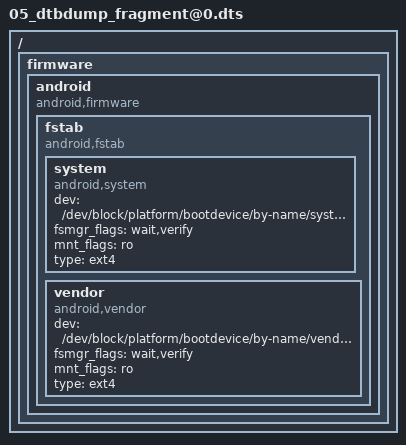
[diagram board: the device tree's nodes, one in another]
/dts-v1/;

/ {

	__fixups__ {
		accdet = "/fragment@17:target:0", "/fragment@62:target:0";
		apuart0 = "/fragment@24:target:0";
		audgpio = "/fragment@18:target:0";
		auxadc = "/fragment@42:target:0";
		chosen = "/fragment@0:target:0";
		consys = "/fragment@21:target:0";
		dsi_te = "/fragment@66:target:0";
		fpc_interrupt = "/fragment@36:target:0";
		goodix_fp = "/fragment@64:target:0";
		goodix_optical_fp = "/fragment@38:target:0";
		gpio = "/fragment@57:target:0";
		gpio_usage_mapping = "/fragment@56:target:0";
		gyro = "/fragment@61:target:0";
		i2c0 = "/fragment@34:target:0", "/fragment@44:target:0";
		i2c1 = "/fragment@45:target:0";
		i2c10 = "/fragment@54:target:0";
		i2c11 = "/fragment@55:target:0";
		i2c2 = "/fragment@46:target:0";
		i2c3 = "/fragment@4:target:0", "/fragment@7:target:0", "/fragment@13:target:0", "/fragment@47:target:0";
		i2c4 = "/fragment@48:target:0";
		i2c5 = "/fragment@11:target:0", "/fragment@49:target:0";
		i2c6 = "/fragment@50:target:0";
		i2c7 = "/fragment@51:target:0";
		i2c8 = "/fragment@52:target:0";
		i2c9 = "/fragment@53:target:0";
		irtx_pwm = "/fragment@26:target:0";
		kd_camera_hw1 = "/fragment@23:target:0", "/fragment@78:target:0";
		keypad = "/fragment@30:target:0", "/fragment@80:target:0";
		main_pmic = "/fragment@67:target:0";
		md1_sim1_hot_plug_eint = "/fragment@69:target:0";
		md1_sim2_hot_plug_eint = "/fragment@70:target:0";
		mediatek_phy_tuning = "/fragment@2:target:0";
		mrdump_ext_rst = "/fragment@58:target:0";
		msdc1 = "/fragment@32:target:0";
		msdc1_ins = "/fragment@60:target:0";
		mt6370_pmu = "/fragment@28:target:0";
		mt6370_typec = "/fragment@29:target:0";
		mt_pmic_vcama1_ldo_reg = "/fragment@23/__overlay__:cam0_vcama-supply:0", "/fragment@71:target:0", "/fragment@78/__overlay__:vcama-supply:0";
		mt_pmic_vcama2_ldo_reg = "/fragment@23/__overlay__:cam1_vcama-supply:0", "/fragment@72:target:0", "/fragment@78/__overlay__:vcama_sub-supply:0";
		mt_pmic_vcamd_ldo_reg = "/fragment@23/__overlay__:cam0_vcamd-supply:0", "/fragment@23/__overlay__:cam1_vcamd-supply:0", "/fragment@75:target:0", "/fragment@78/__overlay__:vcamd_sub-supply:0", "/fragment@78/__overlay__:vcamd-supply:0";
		mt_pmic_vcamio_ldo_reg = "/fragment@23/__overlay__:cam0_vcamio-supply:0", "/fragment@23/__overlay__:cam1_vcamio-supply:0", "/fragment@76:target:0", "/fragment@78/__overlay__:vcamio-supply:0", "/fragment@78/__overlay__:vcamio_sub-supply:0";
		mt_pmic_vio18_ldo_reg = "/fragment@36/__overlay__:vdd_io-supply:0";
		mt_pmic_vldo28_ldo_reg = "/fragment@77:target:0", "/fragment@78/__overlay__:vcamaf-supply:0", "/fragment@79/__overlay__:vtouch-supply:0";
		mt_pmic_vsim1_ldo_reg = "/fragment@73:target:0";
		mt_pmic_vsim2_ldo_reg = "/fragment@74:target:0";
		mtkfb = "/fragment@6:target:0";
		odm = "/fragment@1:target:0";
		oppo_fp_common = "/fragment@40:target:0";
		otg_iddig = "/fragment@15:target:0", "/fragment@65:target:0";
		pio = "/fragment@1/__overlay__/kpd_volume_up:interrupt-parent:0", "/fragment@1/__overlay__/kpd_volume_down:interrupt-parent:0", "/fragment@1/__overlay__/oppo_devinfo:Hw,sub_hwid_1:0", "/fragment@1/__overlay__/oppo_devinfo:Hw,sub_hwid_2:0", "/fragment@1/__overlay__/oppo_devinfo:Hw,main_hwid_5:0", "/fragment@1/__overlay__/oppo_devinfo:Hw,main_hwid_6:0", "/fragment@1/__overlay__/oppo_charger:qcom,chargerid_switch-gpio:0", "/fragment@1/__overlay__/oppo_charger:qcom,ship-gpio:0", "/fragment@1/__overlay__/oppo_charger:qcom,shortc-gpio:0", "/fragment@5:target:0", "/fragment@8:target:0", "/fragment@10:target:0", "/fragment@11/__overlay__/bq24190-charger@6b:interrupt-parent:0", "/fragment@11/__overlay__/bq25890h-charger@6a:interrupt-parent:0", "/fragment@12:target:0", "/fragment@13/__overlay__/dhall0-m1120@0f:interrupt-parent:0", "/fragment@13/__overlay__/dhall0-m1120@0f:dhall,irq-gpio:0", "/fragment@13/__overlay__/dhall0-m1120@0f:hall-power-gpio:0", "/fragment@13/__overlay__/dhall1-m1120@0c:interrupt-parent:0", "/fragment@13/__overlay__/dhall1-m1120@0c:dhall,irq-gpio:0", "/fragment@13/__overlay__/dhall1-m1120@0c:hall-power-gpio:0", "/fragment@14:target:0", "/fragment@16:target:0", "/fragment@19:target:0", "/fragment@20:target:0", "/fragment@22:target:0", "/fragment@25:target:0", "/fragment@27:target:0", "/fragment@28/__overlay__:mt6370,intr_gpio:0", "/fragment@29/__overlay__:mt6370pd,intr_gpio:0", "/fragment@30/__overlay__:keypad,volume-up:0", "/fragment@30/__overlay__:keypad,volume-down:0", "/fragment@31:target:0", "/fragment@33:target:0", "/fragment@34/__overlay__/synatpics_td4310@21:interrupt-parent:0", "/fragment@34/__overlay__/synatpics_td4310@21:irq-gpio:0", "/fragment@34/__overlay__/synatpics_td4330@20:interrupt-parent:0", "/fragment@34/__overlay__/synatpics_td4330@20:irq-gpio:0", "/fragment@34/__overlay__/synatpics_td4330@20:reset-gpio:0", "/fragment@34/__overlay__/himax_hx83112b@48:interrupt-parent:0", "/fragment@34/__overlay__/himax_hx83112b@48:irq-gpio:0", "/fragment@34/__overlay__/himax_hx83112b@48:reset-gpio:0", "/fragment@34/__overlay__/nova_nt36672@62:interrupt-parent:0", "/fragment@34/__overlay__/nova_nt36672@62:irq-gpio:0", "/fragment@34/__overlay__/nova_nt36672@62:reset-gpio:0", "/fragment@35:target:0", "/fragment@36/__overlay__:fpc,irq-gpio:0", "/fragment@36/__overlay__:fpc,reset-gpio:0", "/fragment@36/__overlay__:fpc,vdd-en:0", "/fragment@36/__overlay__:fpc,gpio_cs:0", "/fragment@37:target:0", "/fragment@38/__overlay__:interrupt-parent:0", "/fragment@38/__overlay__:goodix,gpio_irq:0", "/fragment@38/__overlay__:goodix,gpio_reset:0", "/fragment@38/__overlay__:goodix,gpio_ldo:0", "/fragment@38/__overlay__:goodix,gpio_cs:0", "/fragment@39/__overlay__/fingerprint@0:ldo_gpio:0", "/fragment@41:target:0", "/fragment@45/__overlay__/alsps@51:interrupt-parent:0", "/fragment@56/__overlay__:GPIO_SIM2_SIO:0", "/fragment@56/__overlay__:GPIO_SIM2_SRST:0", "/fragment@56/__overlay__:GPIO_SIM2_SCLK:0", "/fragment@56/__overlay__:GPIO_SIM1_SCLK:0", "/fragment@56/__overlay__:GPIO_SIM1_SRST:0", "/fragment@56/__overlay__:GPIO_SIM1_SIO:0", "/fragment@56/__overlay__:GPIO_SIM2_HOT_PLUG:0", "/fragment@56/__overlay__:GPIO_SIM1_HOT_PLUG:0", "/fragment@58/__overlay__:interrupt-parent:0", "/fragment@58/__overlay__:deb-gpios:0", "/fragment@59/__overlay__:interrupt-parent:0", "/fragment@60/__overlay__:interrupt-parent:0", "/fragment@60/__overlay__:deb-gpios:0", "/fragment@61/__overlay__:interrupt-parent:0", "/fragment@62/__overlay__:interrupt-parent:0", "/fragment@62/__overlay__:deb-gpios:0", "/fragment@63/__overlay__:interrupt-parent:0", "/fragment@64/__overlay__:interrupt-parent:0", "/fragment@65/__overlay__:interrupt-parent:0", "/fragment@66/__overlay__:interrupt-parent:0", "/fragment@67/__overlay__:interrupt-parent:0", "/fragment@68/__overlay__:interrupt-parent:0";
		pmic_clock_buffer_ctrl = "/fragment@43:target:0";
		scp = "/fragment@3:target:0";
		smart_pa = "/fragment@68:target:0";
		spi0 = "/fragment@39:target:0";
		subpmic_pmu_eint = "/fragment@63:target:0";
		touch = "/fragment@9:target:0", "/fragment@59:target:0", "/fragment@79:target:0";
	};

	__local_fixups__ {

		fragment@1 {

			__overlay__ {

				oppo_charger {
					pinctrl-0 = <0x0>;
					pinctrl-1 = <0x0>;
					pinctrl-2 = <0x0>;
					pinctrl-3 = <0x0>;
					pinctrl-4 = <0x0>;
					pinctrl-5 = <0x0>;
				};

				oppo_devinfo {
					pinctrl-0 = <0x0>;
					pinctrl-1 = <0x0 0x4>;
					pinctrl-2 = <0x0 0x4>;
					pinctrl-3 = <0x0>;
					pinctrl-4 = <0x0>;
				};
			};
		};

		fragment@13 {

			__overlay__ {

				dhall0-m1120@0f {
					pinctrl-0 = <0x0>;
					pinctrl-1 = <0x0>;
					pinctrl-2 = <0x0>;
				};

				dhall1-m1120@0c {
					pinctrl-0 = <0x0>;
					pinctrl-1 = <0x0>;
					pinctrl-2 = <0x0>;
				};
			};
		};

		fragment@15 {

			__overlay__ {
				pinctrl-0 = <0x0>;
				pinctrl-1 = <0x0>;
				pinctrl-2 = <0x0>;
			};
		};

		fragment@18 {

			__overlay__ {
				pinctrl-0 = <0x0>;
				pinctrl-1 = <0x0>;
				pinctrl-10 = <0x0>;
				pinctrl-11 = <0x0>;
				pinctrl-2 = <0x0>;
				pinctrl-3 = <0x0>;
				pinctrl-4 = <0x0>;
				pinctrl-5 = <0x0>;
				pinctrl-6 = <0x0>;
				pinctrl-7 = <0x0>;
				pinctrl-8 = <0x0>;
				pinctrl-9 = <0x0>;
			};
		};

		fragment@21 {

			__overlay__ {
				pinctrl-0 = <0x0>;
				pinctrl-1 = <0x0>;
				pinctrl-2 = <0x0>;
				pinctrl-3 = <0x0>;
			};
		};

		fragment@23 {

			__overlay__ {
				pinctrl-0 = <0x0>;
				pinctrl-1 = <0x0>;
				pinctrl-10 = <0x0>;
				pinctrl-11 = <0x0>;
				pinctrl-12 = <0x0>;
				pinctrl-13 = <0x0>;
				pinctrl-14 = <0x0>;
				pinctrl-15 = <0x0>;
				pinctrl-16 = <0x0>;
				pinctrl-17 = <0x0>;
				pinctrl-18 = <0x0>;
				pinctrl-19 = <0x0>;
				pinctrl-2 = <0x0>;
				pinctrl-20 = <0x0>;
				pinctrl-21 = <0x0>;
				pinctrl-22 = <0x0>;
				pinctrl-23 = <0x0>;
				pinctrl-24 = <0x0>;
				pinctrl-25 = <0x0>;
				pinctrl-26 = <0x0>;
				pinctrl-27 = <0x0>;
				pinctrl-28 = <0x0>;
				pinctrl-29 = <0x0>;
				pinctrl-3 = <0x0>;
				pinctrl-30 = <0x0>;
				pinctrl-31 = <0x0>;
				pinctrl-32 = <0x0>;
				pinctrl-33 = <0x0>;
				pinctrl-4 = <0x0>;
				pinctrl-5 = <0x0>;
				pinctrl-6 = <0x0>;
				pinctrl-7 = <0x0>;
				pinctrl-8 = <0x0>;
				pinctrl-9 = <0x0>;
			};
		};

		fragment@24 {

			__overlay__ {
				pinctrl-0 = <0x0>;
				pinctrl-1 = <0x0>;
				pinctrl-2 = <0x0>;
				pinctrl-3 = <0x0>;
				pinctrl-4 = <0x0>;
				pinctrl-5 = <0x0>;
				pinctrl-6 = <0x0>;
			};
		};

		fragment@26 {

			__overlay__ {
				pinctrl-0 = <0x0>;
				pinctrl-1 = <0x0>;
			};
		};

		fragment@30 {

			__overlay__ {
				pinctrl-0 = <0x0>;
				pinctrl-1 = <0x0>;
			};
		};

		fragment@32 {

			__overlay__ {
				pinctrl-0 = <0x0>;
				pinctrl-1 = <0x0>;
			};
		};

		fragment@36 {

			__overlay__ {
				pinctrl-0 = <0x0 0x4 0x8>;
				pinctrl-1 = <0x0>;
			};
		};

		fragment@38 {

			__overlay__ {
				pinctrl-0 = <0x0>;
				pinctrl-1 = <0x0>;
				pinctrl-2 = <0x0>;
				pinctrl-3 = <0x0>;
				pinctrl-4 = <0x0>;
			};
		};

		fragment@6 {

			__overlay__ {
				pinctrl-0 = <0x0>;
				pinctrl-1 = <0x0>;
				pinctrl-10 = <0x0>;
				pinctrl-11 = <0x0>;
				pinctrl-12 = <0x0>;
				pinctrl-2 = <0x0>;
				pinctrl-3 = <0x0>;
				pinctrl-4 = <0x0>;
				pinctrl-5 = <0x0>;
				pinctrl-6 = <0x0>;
				pinctrl-7 = <0x0>;
				pinctrl-8 = <0x0>;
				pinctrl-9 = <0x0>;
			};
		};

		fragment@7 {

			__overlay__ {

				tfa98xx@35 {
					pinctrl-0 = <0x0>;
					pinctrl-1 = <0x0>;
					pinctrl-2 = <0x0>;
				};
			};
		};

		fragment@9 {

			__overlay__ {
				pinctrl-0 = <0x0>;
				pinctrl-1 = <0x0>;
				pinctrl-2 = <0x0>;
				pinctrl-3 = <0x0>;
				pinctrl-4 = <0x0>;
				pinctrl-5 = <0x0>;
			};
		};
	};

	__symbols__ {
		alsps_mtk = "/fragment@45/__overlay__/alsps@51";
		aud_clk_mosi_off = "/fragment@19/__overlay__/aud_clk_mosi_off";
		aud_clk_mosi_on = "/fragment@19/__overlay__/aud_clk_mosi_on";
		aud_dat_miso_off = "/fragment@19/__overlay__/aud_dat_miso_off";
		aud_dat_miso_on = "/fragment@19/__overlay__/aud_dat_miso_on";
		aud_dat_mosi_off = "/fragment@19/__overlay__/aud_dat_mosi_off";
		aud_dat_mosi_on = "/fragment@19/__overlay__/aud_dat_mosi_on";
		aud_pins_hpamp_high = "/fragment@19/__overlay__/audhpamphigh";
		aud_pins_hpamp_low = "/fragment@19/__overlay__/audhpamplow";
		aud_pins_i2s0_mode0 = "/fragment@19/__overlay__/audi2s0mode0";
		aud_pins_i2s0_mode1 = "/fragment@19/__overlay__/audi2s0mode1";
		aud_pins_i2s1_mode0 = "/fragment@19/__overlay__/audi2s1mode0";
		aud_pins_i2s1_mode1 = "/fragment@19/__overlay__/audi2s1mode1";
		barometer_mtk = "/fragment@45/__overlay__/barometer@77";
		bat_gm30 = "/fragment@1/__overlay__/bat_gm30";
		camera_main_af_mtk = "/fragment@48/__overlay__/camera_main_af@72";
		camera_main_eeprom_mtk = "/fragment@48/__overlay__/camera_main_eeprom@50";
		camera_main_mtk = "/fragment@48/__overlay__/camera_main@1a";
		camera_main_two_af_mtk = "/fragment@48/__overlay__/camera_main_two_af@72";
		camera_main_two_eeprom_mtk = "/fragment@48/__overlay__/camera_main_two_eeprom@51";
		camera_main_two_mtk = "/fragment@48/__overlay__/camera_main_two@10";
		camera_pins_cam0_mclk_2ma = "/fragment@22/__overlay__/camera_pins_cam0_mclk_2ma";
		camera_pins_cam0_mclk_4ma = "/fragment@22/__overlay__/camera_pins_cam0_mclk_4ma";
		camera_pins_cam0_mclk_6ma = "/fragment@22/__overlay__/camera_pins_cam0_mclk_6ma";
		camera_pins_cam0_mclk_8ma = "/fragment@22/__overlay__/camera_pins_cam0_mclk_8ma";
		camera_pins_cam0_mclk_off = "/fragment@22/__overlay__/camera_pins_cam0_mclk_off";
		camera_pins_cam0_pnd_0 = "/fragment@22/__overlay__/cam0@2";
		camera_pins_cam0_pnd_1 = "/fragment@22/__overlay__/cam0@3";
		camera_pins_cam0_rst_0 = "/fragment@22/__overlay__/cam0@0";
		camera_pins_cam0_rst_1 = "/fragment@22/__overlay__/cam0@1";
		camera_pins_cam0_vcamd_0 = "/fragment@22/__overlay__/cam0@vcam0";
		camera_pins_cam0_vcamd_1 = "/fragment@22/__overlay__/cam0@vcam1";
		camera_pins_cam1_mclk_2ma = "/fragment@22/__overlay__/camera_pins_cam1_mclk_2ma";
		camera_pins_cam1_mclk_4ma = "/fragment@22/__overlay__/camera_pins_cam1_mclk_4ma";
		camera_pins_cam1_mclk_6ma = "/fragment@22/__overlay__/camera_pins_cam1_mclk_6ma";
		camera_pins_cam1_mclk_8ma = "/fragment@22/__overlay__/camera_pins_cam1_mclk_8ma";
		camera_pins_cam1_mclk_off = "/fragment@22/__overlay__/camera_pins_cam1_mclk_off";
		camera_pins_cam1_pnd_0 = "/fragment@22/__overlay__/cam1@2";
		camera_pins_cam1_pnd_1 = "/fragment@22/__overlay__/cam1@3";
		camera_pins_cam1_rst_0 = "/fragment@22/__overlay__/cam1@0";
		camera_pins_cam1_rst_1 = "/fragment@22/__overlay__/cam1@1";
		camera_pins_cam2_mclk_2ma = "/fragment@22/__overlay__/camera_pins_cam2_mclk_2ma";
		camera_pins_cam2_mclk_4ma = "/fragment@22/__overlay__/camera_pins_cam2_mclk_4ma";
		camera_pins_cam2_mclk_6ma = "/fragment@22/__overlay__/camera_pins_cam2_mclk_6ma";
		camera_pins_cam2_mclk_8ma = "/fragment@22/__overlay__/camera_pins_cam2_mclk_8ma";
		camera_pins_cam2_mclk_off = "/fragment@22/__overlay__/camera_pins_cam2_mclk_off";
		camera_pins_cam2_pnd_0 = "/fragment@22/__overlay__/cam2@3";
		camera_pins_cam2_pnd_1 = "/fragment@22/__overlay__/cam2@4";
		camera_pins_cam2_rst_0 = "/fragment@22/__overlay__/cam2@0";
		camera_pins_cam2_rst_1 = "/fragment@22/__overlay__/cam2@1";
		camera_pins_cam2_vcama_0 = "/fragment@22/__overlay__/cam1@vcam2";
		camera_pins_cam2_vcama_1 = "/fragment@22/__overlay__/cam1@vcam3";
		camera_pins_cam2_vcamd_0 = "/fragment@22/__overlay__/cam2@vcam0";
		camera_pins_cam2_vcamd_1 = "/fragment@22/__overlay__/cam1@vcam1";
		camera_pins_default = "/fragment@22/__overlay__/camdefault";
		camera_sub_eeprom_mtk = "/fragment@48/__overlay__/camera_sub_eeprom@54";
		camera_sub_mtk = "/fragment@48/__overlay__/camera_sub@35";
		cap_touch_mtk = "/fragment@44/__overlay__/cap_touch@5d";
		ccu_sensor_i2c_4_hw_mtk = "/fragment@48/__overlay__/ccu_sensor_i2c_4_hw@33";
		charger_pins_default = "/fragment@12/__overlay__/eint0default";
		charger_pins_eint_output0 = "/fragment@12/__overlay__/charger_gpio_as_output_low";
		charger_pins_eint_output1 = "/fragment@12/__overlay__/charger_gpio_as_output_high";
		consys_pins_default = "/fragment@20/__overlay__/consys_default";
		ctp_pins_default = "/fragment@10/__overlay__/eint0default";
		ctp_pins_eint_as_int = "/fragment@10/__overlay__/eint@0";
		ctp_pins_eint_output0 = "/fragment@10/__overlay__/eintoutput0";
		ctp_pins_eint_output1 = "/fragment@10/__overlay__/eintoutput1";
		ctp_pins_rst_output0 = "/fragment@10/__overlay__/rstoutput0";
		ctp_pins_rst_output1 = "/fragment@10/__overlay__/rstoutput1";
		fpc_irq_default = "/fragment@35/__overlay__/fpc_irq_default";
		fpc_pwr_default = "/fragment@35/__overlay__/fpc_pwr_default";
		fpc_reset_default = "/fragment@35/__overlay__/fpc_reset_default";
		fuelgauge = "/fragment@1/__overlay__/fuelgauge";
		goodix_irq_no_pull = "/fragment@37/__overlay__/goodix_irq_no_pull";
		goodix_irq_out_low = "/fragment@37/__overlay__/goodix_irq_out_low";
		goodix_ldo_default = "/fragment@37/__overlay__/goodix_ldo_default";
		goodix_reset_default = "/fragment@37/__overlay__/goodix_reset_default";
		gpio41_gpio_mode = "/fragment@16/__overlay__/id_output_low";
		gpio41_mode1_iddig = "/fragment@16/__overlay__/id_init";
		gpio_fpc_cs_func = "/fragment@35/__overlay__/gpio_fpc_cs_func";
		gpio_goodix_cs_func = "/fragment@37/__overlay__/gpio_goodix_cs_func";
		gpslna_pins_init = "/fragment@20/__overlay__/gpslna@0";
		gpslna_pins_oh = "/fragment@20/__overlay__/gpslna@1";
		gpslna_pins_ol = "/fragment@20/__overlay__/gpslna@2";
		hall0_interrupt_input = "/fragment@14/__overlay__/hall0_interrupt_input";
		hall1_interrupt_input = "/fragment@14/__overlay__/hall1_interrupt_input";
		hall_power_down = "/fragment@14/__overlay__/hall_power_down";
		hall_power_up = "/fragment@14/__overlay__/hall_power_up";
		hw_main_id5_active = "/fragment@41/__overlay__/active@id5";
		hw_main_id6_active = "/fragment@41/__overlay__/active@id6";
		hw_pins_default = "/fragment@41/__overlay__/default@hw_sub_id";
		hw_pins_sub_id1_active = "/fragment@41/__overlay__/active@id1";
		hw_pins_sub_id1_sleep = "/fragment@41/__overlay__/sleep@id1";
		hw_pins_sub_id2_active = "/fragment@41/__overlay__/active@id2";
		hw_pins_sub_id2_sleep = "/fragment@41/__overlay__/sleep@id2";
		iddig_default = "/fragment@16/__overlay__/id_default";
		irtx_gpio_led_default = "/fragment@27/__overlay__/irtx_gpio_led_def@gpio90";
		irtx_gpio_led_set = "/fragment@27/__overlay__/irtx_gpio_led_set@gpio90";
		kpd_volume_down = "/fragment@1/__overlay__/kpd_volume_down";
		kpd_volume_up = "/fragment@1/__overlay__/kpd_volume_up";
		led0 = "/fragment@1/__overlay__/led@0";
		led1 = "/fragment@1/__overlay__/led@1";
		led2 = "/fragment@1/__overlay__/led@2";
		led3 = "/fragment@1/__overlay__/led@3";
		led4 = "/fragment@1/__overlay__/led@4";
		led5 = "/fragment@1/__overlay__/led@5";
		led6 = "/fragment@1/__overlay__/led@6";
		msdc1_off = "/fragment@33/__overlay__/sd0@1";
		msdc1_on = "/fragment@33/__overlay__/sd0@0";
		msensor_mtk = "/fragment@45/__overlay__/msensor@0c";
		mtkfb_pins_default = "/fragment@5/__overlay__/default";
		mtkfb_pins_lcd_1p8_en0 = "/fragment@5/__overlay__/lcd_1p8_en0_gpio";
		mtkfb_pins_lcd_1p8_en1 = "/fragment@5/__overlay__/lcd_1p8_en1_gpio";
		mtkfb_pins_lcd_bias_enn0 = "/fragment@5/__overlay__/lcd_bias_enn0_gpio";
		mtkfb_pins_lcd_bias_enn1 = "/fragment@5/__overlay__/lcd_bias_enn1_gpio";
		mtkfb_pins_lcd_bias_enp0 = "/fragment@5/__overlay__/lcd_bias_enp0_gpio";
		mtkfb_pins_lcd_bias_enp1 = "/fragment@5/__overlay__/lcd_bias_enp1_gpio";
		mtkfb_pins_lcd_bl_en0 = "/fragment@5/__overlay__/lcd_bl_en0_gpio";
		mtkfb_pins_lcd_bl_en1 = "/fragment@5/__overlay__/lcd_bl_en1_gpio";
		mtkfb_pins_lcm_reset0 = "/fragment@5/__overlay__/lcm_rst_out0_gpio";
		mtkfb_pins_lcm_reset1 = "/fragment@5/__overlay__/lcm_rst_out1_gpio";
		mtkfb_pins_mode_te_gpio = "/fragment@5/__overlay__/mode_te_gpio";
		mtkfb_pins_mode_te_te = "/fragment@5/__overlay__/mode_te_te";
		nfc_mtk = "/fragment@47/__overlay__/nfc@08";
		oppo_charger = "/fragment@1/__overlay__/oppo_charger";
		oppo_devinfo = "/fragment@1/__overlay__/oppo_devinfo";
		oppo_fp = "/fragment@39/__overlay__/fingerprint@0";
		oppo_project = "/fragment@1/__overlay__/oppo_project";
		oppo_sensor = "/fragment@1/__overlay__/oppo_sensor";
		ship_active_gpio = "/fragment@12/__overlay__/ship_active";
		ship_sleep_gpio = "/fragment@12/__overlay__/ship_sleep";
		shortc_active_gpio = "/fragment@12/__overlay__/shortc_active";
		slave_charger_mtk = "/fragment@50/__overlay__/slave_charger@4b";
		speaker_amp_mtk = "/fragment@50/__overlay__/speaker_amp@34";
		strobe_main_mtk = "/fragment@48/__overlay__/strobe_main@63";
		subpmic_pmu_mtk = "/fragment@49/__overlay__/subpmic_pmu@34";
		tfa98xxresetdefault = "/fragment@8/__overlay__/tfa98xxrstdefault";
		tfa98xxresethigh = "/fragment@8/__overlay__/tfa98xxrsthigh";
		tfa98xxresetlow = "/fragment@8/__overlay__/tfa98xxrstlow";
		uart0_gpio_def_cfg = "/fragment@25/__overlay__/uart0gpiodefault";
		uart0_rx_clr_cfg = "/fragment@25/__overlay__/uart0_rx_clear@gpio95";
		uart0_rx_gpio_input2 = "/fragment@25/__overlay__/uart0_rx_gpio@gpio95";
		uart0_rx_set_cfg = "/fragment@25/__overlay__/uart0_rx_set@gpio95";
		uart0_tx_clr_cfg = "/fragment@25/__overlay__/uart0_tx_clear@gpio96";
		uart0_tx_gpio_input2 = "/fragment@25/__overlay__/uart0_tx_gpio@gpio96";
		uart0_tx_set_cfg = "/fragment@25/__overlay__/uart0_tx_set@gpio96";
		usb_type_c_mtk = "/fragment@49/__overlay__/usb_type_c@4e";
		vibrator0 = "/fragment@1/__overlay__/vibrator@0";
		volume_down_gpio_eint = "/fragment@31/__overlay__/volume_down@0";
		volume_up_gpio_eint = "/fragment@31/__overlay__/volume_up@0";
	};

	firmware {

		android {
			compatible = "android,firmware";

			fstab {
				compatible = "android,fstab";

				system {
					compatible = "android,system";
					dev = "/dev/block/platform/bootdevice/by-name/system";
					fsmgr_flags = "wait,verify";
					mnt_flags = "ro";
					type = "ext4";
				};

				vendor {
					compatible = "android,vendor";
					dev = "/dev/block/platform/bootdevice/by-name/vendor";
					fsmgr_flags = "wait,verify";
					mnt_flags = "ro";
					type = "ext4";
				};
			};
		};
	};

	fragment@0 {
		target = <0xffffffff>;

		__overlay__ {
			atag,videolfb-fb_base_h = <0x0>;
			atag,videolfb-fb_base_l = "^`P";
			atag,videolfb-fps = <0x1770>;
			atag,videolfb-islcm_inited = <0x0>;
			atag,videolfb-islcmfound = <0x1>;
			atag,videolfb-lcmname = "nt35595_fhd_dsi_cmd_truly_nt50358_drv";
			atag,videolfb-vramSize = <0x17bb000>;
		};
	};

	fragment@1 {
		target = <0xffffffff>;

		__overlay__ {

			bat_gm30 {
				CAR_TUNE_VALUE = <0x64>;
				DIFFERENCE_FULLOCV_ITH = <0xc8>;
				EMBEDDED_SEL = <0x1>;
				FG_METER_RESISTANCE = <0x4b>;
				KEEP_100_PERCENT = <0x0>;
				PMIC_MIN_VOL = <0x84d0>;
				PMIC_SHUTDOWN_CURRENT = <0x14>;
				POWERON_SYSTEM_IBOOT = <0x1f4>;
				Q_MAX_SYS_VOLTAGE_BAT0 = <0xd16>;
				Q_MAX_SYS_VOLTAGE_BAT1 = <0xd16>;
				Q_MAX_SYS_VOLTAGE_BAT2 = <0xd16>;
				Q_MAX_SYS_VOLTAGE_BAT3 = <0xd16>;
				R_FG_VALUE = <0xa>;
				SHUTDOWN_1_TIME = <0x3c>;
				SHUTDOWN_GAUGE0_VOLTAGE = <0x84d0>;
				TEMPERATURE_T0 = <0x32>;
				TEMPERATURE_T1 = <0x19>;
				TEMPERATURE_T2 = <0xa>;
				TEMPERATURE_T3 = <0x0>;
				TEMPERATURE_T4 = <0xfffffff6>;
				battery0_profile_t0 = <0x0 0xa9b0 0x339 0x14f 0xa937 0x3ae 0x29f 0xa8c2 0x3f1 0x3ee 0xa850 0x401 0x53e 0xa7d4 0x3f0 0x68d 0xa75b 0x3e8 0x7dd 0xa6e2 0x3e8 0x92c 0xa669 0x3e8 0xa7c 0xa5f8 0x3fb 0xbcb 0xa58c 0x41a 0xd1b 0xa51a 0x41a 0xe6a 0xa49e 0x406 0xfb9 0xa41f 0x3ed 0x1109 0xa3b4 0x40e 0x1258 0xa344 0x41a 0x13a8 0xa2d2 0x41a 0x14f7 0xa260 0x41a 0x1647 0xa1ee 0x41a 0x1796 0xa17d 0x41a 0x18e6 0xa10f 0x41a 0x1a35 0xa0a3 0x426 0x1b85 0xa038 0x42f 0x1cd4 0x9fcd 0x41e 0x1e23 0x9f61 0x41a 0x1f73 0x9ef9 0x41e 0x20c2 0x9e9b 0x42f 0x2212 0x9e3c 0x440 0x2361 0x9dd9 0x44c 0x24b1 0x9d6e 0x44c 0x2600 0x9d0d 0x44c 0x2750 0x9cb1 0x451 0x289f 0x9c5a 0x462 0x29ef 0x9c03 0x465 0x2b3e 0x9bb0 0x470 0x2c8d 0x9b66 0x492 0x2ddd 0x9b15 0x4a5 0x2f2c 0x9ac1 0x4b0 0x307c 0x9a6a 0x4b0 0x31cb 0x9a1f 0x4eb 0x331b 0x99ca 0x50d 0x346a 0x9966 0x4fd 0x35ba 0x98ca 0x491 0x3709 0x983f 0x437 0x3859 0x97d1 0x403 0x39a8 0x9786 0x411 0x3af7 0x973f 0x412 0x3c47 0x96fc 0x401 0x3d96 0x96bf 0x3f1 0x3ee6 0x9683 0x3e8 0x4035 0x9646 0x3e8 0x4185 0x9616 0x3f9 0x42d4 0x95eb 0x40a 0x4424 0x95c2 0x419 0x4573 0x958c 0x409 0x46c3 0x955e 0x40a 0x4812 0x9536 0x41a 0x4961 0x950d 0x41a 0x4ab1 0x94e9 0x424 0x4c00 0x94c6 0x431 0x4d50 0x949d 0x420 0x4e9f 0x9479 0x424 0x4fef 0x9458 0x435 0x513e 0x9436 0x446 0x528e 0x9419 0x44c 0x53dd 0x93ff 0x451 0x552d 0x93ea 0x473 0x567c 0x93d2 0x48a 0x57cb 0x93b3 0x494 0x591b 0x9384 0x483 0x5a6a 0x933d 0x443 0x5bba 0x92f1 0x401 0x5d09 0x92b5 0x401 0x5e59 0x9281 0x40d 0x5fa8 0x9252 0x416 0x60f8 0x9223 0x405 0x6247 0x91fe 0x41b 0x6397 0x91db 0x42a 0x64e6 0x91b2 0x408 0x6635 0x9195 0x41c 0x6785 0x9174 0x433 0x68d4 0x9144 0x433 0x6a24 0x9109 0x425 0x6b73 0x90cd 0x41a 0x6cc3 0x9091 0x41a 0x6e12 0x9054 0x428 0x6f62 0x9015 0x42d 0x70b1 0x8fd2 0x41c 0x7201 0x8fb8 0x40b 0x7350 0x8fa9 0x40f 0x749f 0x8fa2 0x431 0x75ef 0x8f96 0x462 0x773e 0x8f74 0x494 0x788e 0x8f37 0x4c6 0x79dd 0x8e10 0x48a 0x7b2d 0x8c7a 0x47c 0x7c7c 0x8a6e 0x4ae 0x7dcc 0x8722 0x4f2 0x7f1b 0x8167 0x797 0x806b 0x7841 0x7d0 0x81ba 0x7706 0x52d>;
				battery0_profile_t0_num = <0x64>;
				battery0_profile_t1 = <0x0 0xa9ce 0x47e 0x14f 0xa948 0x4e3 0x29f 0xa8c5 0x514 0x3ee 0xa846 0x515 0x53e 0xa7ca 0x537 0x68d 0xa754 0x53d 0x7dd 0xa6e2 0x52c 0x92c 0xa669 0x51b 0xa7c 0xa5f8 0x527 0xbcb 0xa58b 0x545 0xd1b 0xa50b 0x534 0xe6a 0xa498 0x52d 0xfb9 0xa42c 0x531 0x1109 0xa3ba 0x552 0x1258 0xa348 0x55f 0x13a8 0xa2d7 0x561 0x14f7 0xa26b 0x572 0x1647 0xa1f6 0x557 0x1796 0xa17d 0x536 0x18e6 0xa112 0x568 0x1a35 0xa0a7 0x578 0x1b85 0xa03d 0x578 0x1cd4 0x9fd8 0x578 0x1e23 0x9f73 0x584 0x1f73 0x9f11 0x595 0x20c2 0x9eb8 0x5a6 0x2212 0x9e56 0x5b7 0x2361 0x9dee 0x5c3 0x24b1 0x9d7c 0x5c3 0x2600 0x9d15 0x5dd 0x2750 0x9cb2 0x5fa 0x289f 0x9c54 0x60a 0x29ef 0x9bfb 0x61b 0x2b3e 0x9ba6 0x62c 0x2c8d 0x9b55 0x63d 0x2ddd 0x9b14 0x65c 0x2f2c 0x9ad2 0x678 0x307c 0x9a89 0x689 0x31cb 0x9a33 0x699 0x331b 0x99d7 0x69e 0x346a 0x9973 0x68d 0x35ba 0x98eb 0x616 0x3709 0x9866 0x59c 0x3859 0x97ed 0x538 0x39a8 0x9792 0x51e 0x3af7 0x9746 0x51b 0x3c47 0x9709 0x52c 0x3d96 0x96d3 0x53c 0x3ee6 0x969a 0x538 0x4035 0x965c 0x515 0x4185 0x9626 0x514 0x42d4 0x95f7 0x51c 0x4424 0x95cf 0x52d 0x4573 0x95a0 0x52d 0x46c3 0x9574 0x535 0x4812 0x954c 0x546 0x4961 0x9524 0x546 0x4ab1 0x94fb 0x53d 0x4c00 0x94d3 0x52e 0x4d50 0x94b8 0x550 0x4e9f 0x9499 0x55f 0x4fef 0x9478 0x560 0x513e 0x945d 0x571 0x528e 0x943f 0x578 0x53dd 0x941e 0x579 0x552d 0x940a 0x58a 0x567c 0x93f6 0x5a5 0x57cb 0x93e0 0x5c1 0x591b 0x93bf 0x5b0 0x5a6a 0x939d 0x595 0x5bba 0x937b 0x575 0x5d09 0x9359 0x565 0x5e59 0x9333 0x554 0x5fa8 0x930a 0x540 0x60f8 0x92db 0x51f 0x6247 0x92b5 0x514 0x6397 0x9293 0x51b 0x64e6 0x9271 0x53d 0x6635 0x924f 0x546 0x6785 0x922e 0x54a 0x68d4 0x920c 0x55b 0x6a24 0x91d7 0x552 0x6b73 0x919c 0x54a 0x6cc3 0x9166 0x55b 0x6e12 0x9130 0x56c 0x6f62 0x90f1 0x573 0x70b1 0x90a1 0x562 0x7201 0x9066 0x551 0x7350 0x9040 0x551 0x749f 0x9039 0x573 0x75ef 0x9032 0x5a2 0x773e 0x9025 0x5cf 0x788e 0x900a 0x5f0 0x79dd 0x8fb0 0x612 0x7b2d 0x8edd 0x61b 0x7c7c 0x8d4a 0x5f9 0x7dcc 0x8aeb 0x640 0x7f1b 0x87b3 0x6be 0x806b 0x8374 0x777 0x81ba 0x77c4 0x6bd>;
				battery0_profile_t1_num = <0x64>;
				battery0_profile_t2 = <0x0 0xa956 0x8b1 0x14f 0xa8b5 0x82b 0x29f 0xa825 0x7fa 0x3ee 0xa7a6 0x81b 0x53e 0xa726 0x81b 0x68d 0xa6aa 0x824 0x7dd 0xa631 0x834 0x92c 0xa5b9 0x834 0xa7c 0xa544 0x846 0xbcb 0xa4d1 0x865 0xd1b 0xa456 0x854 0xe6a 0xa3e0 0x84d 0xfb9 0xa36e 0x84f 0x1109 0xa2fc 0x860 0x1258 0xa28e 0x870 0x13a8 0xa222 0x87f 0x14f7 0xa1b0 0x87f 0x1647 0xa142 0x88a 0x1796 0xa0d7 0x89a 0x18e6 0xa06b 0x8ab 0x1a35 0xa004 0x8b1 0x1b85 0x9fa2 0x8b6 0x1cd4 0x9f4b 0x8d8 0x1e23 0x9ef3 0x905 0x1f73 0x9e97 0x937 0x20c2 0x9e25 0x969 0x2212 0x9d9f 0x956 0x2361 0x9d13 0x92e 0x24b1 0x9c93 0x92e 0x2600 0x9c31 0x947 0x2750 0x9bdf 0x968 0x289f 0x9b9c 0x98a 0x29ef 0x9b54 0x992 0x2b3e 0x9b08 0x98e 0x2c8d 0x9ab8 0x97d 0x2ddd 0x9a72 0x993 0x2f2c 0x9a27 0x9a1 0x307c 0x99c9 0x980 0x31cb 0x9950 0x929 0x331b 0x98d1 0x8c4 0x346a 0x9851 0x860 0x35ba 0x97ed 0x832 0x3709 0x9794 0x810 0x3859 0x9743 0x7ef 0x39a8 0x96fd 0x7db 0x3af7 0x96bb 0x7d0 0x3c47 0x967f 0x7d0 0x3d96 0x964f 0x7df 0x3ee6 0x961d 0x7e9 0x4035 0x95e7 0x7e9 0x4185 0x95b8 0x7e9 0x42d4 0x958e 0x7f7 0x4424 0x956d 0x818 0x4573 0x953f 0x81b 0x46c3 0x9516 0x822 0x4812 0x94f4 0x833 0x4961 0x94cc 0x834 0x4ab1 0x94aa 0x843 0x4c00 0x948e 0x866 0x4d50 0x946d 0x866 0x4e9f 0x944f 0x86e 0x4fef 0x9434 0x87f 0x513e 0x9419 0x87f 0x528e 0x93fe 0x87f 0x53dd 0x93e3 0x87f 0x552d 0x93cf 0x890 0x567c 0x93bb 0x898 0x57cb 0x93a7 0x899 0x591b 0x9393 0x8aa 0x5a6a 0x937e 0x8bb 0x5bba 0x9369 0x8ca 0x5d09 0x934f 0x8ca 0x5e59 0x9330 0x8ca 0x5fa8 0x930d 0x8c8 0x60f8 0x92de 0x8b7 0x6247 0x92b7 0x8bb 0x6397 0x9296 0x8d1 0x64e6 0x9274 0x903 0x6635 0x9246 0x920 0x6785 0x920f 0x931 0x68d4 0x91d2 0x941 0x6a24 0x919a 0x969 0x6b73 0x915f 0x995 0x6cc3 0x9115 0x9a6 0x6e12 0x90cc 0x9c3 0x6f62 0x908c 0x9ec 0x70b1 0x9071 0xa2f 0x7201 0x905b 0xa7e 0x7350 0x9049 0xae2 0x749f 0x903b 0xb79 0x75ef 0x9014 0xc2c 0x773e 0x8fad 0xcdd 0x788e 0x8ebb 0xd74 0x79dd 0x8cde 0xe84 0x7b2d 0x8a65 0x1028 0x7c7c 0x8711 0x12d7 0x7dcc 0x8115 0x1734 0x7f1b 0x78c8 0x960 0x806b 0x78c8 0x960 0x81ba 0x78c8 0x960>;
				battery0_profile_t2_num = <0x64>;
				battery0_profile_t3 = <0x0 0xa87a 0xf23 0x14f 0xa7cc 0xcb6 0x29f 0xa735 0xba8 0x3ee 0xa6b6 0xbea 0x53e 0xa63d 0xbfb 0x68d 0xa5c1 0xc03 0x7dd 0xa542 0xc04 0x92c 0xa4cd 0xc15 0xa7c 0xa45a 0xc1c 0xbcb 0xa3e8 0xc1d 0xd1b 0xa376 0xc2e 0xe6a 0xa300 0xc2b 0xfb9 0xa289 0xc1e 0x1109 0xa21d 0xc2f 0x1258 0xa1b2 0xc3f 0x13a8 0xa147 0xc50 0x14f7 0xa0db 0xc61 0x1647 0xa070 0xc5c 0x1796 0xa006 0xc53 0x18e6 0x9fa6 0xc75 0x1a35 0x9f51 0xcae 0x1b85 0x9efe 0xcee 0x1cd4 0x9ea0 0xd20 0x1e23 0x9e21 0xd17 0x1f73 0x9d91 0xcf2 0x20c2 0x9cf7 0xcc0 0x2212 0x9c75 0xcb2 0x2361 0x9c04 0xcb6 0x24b1 0x9bad 0xcc7 0x2600 0x9b64 0xce4 0x2750 0x9b20 0xcf9 0x289f 0x9ad6 0xce8 0x29ef 0x9a82 0xcd7 0x2b3e 0x9a2b 0xcc2 0x2c8d 0x99d3 0xca0 0x2ddd 0x996d 0xc58 0x2f2c 0x98ff 0xc04 0x307c 0x988d 0xbb0 0x31cb 0x982b 0xb84 0x331b 0x97d1 0xb63 0x346a 0x9781 0xb41 0x35ba 0x9736 0xb2d 0x3709 0x96ee 0xb22 0x3859 0x96ab 0xb22 0x39a8 0x9679 0xb30 0x3af7 0x9648 0xb3b 0x3c47 0x9612 0xb3b 0x3d96 0x95e2 0xb49 0x3ee6 0x95b3 0xb5a 0x4035 0x9583 0xb6b 0x4185 0x9554 0xb6d 0x42d4 0x952d 0xb7b 0x4424 0x9512 0xb9c 0x4573 0x94eb 0xbae 0x46c3 0x94c6 0xbb8 0x4812 0x94a4 0xbb8 0x4961 0x9482 0xbd8 0x4ab1 0x9461 0xbea 0x4c00 0x943e 0xbea 0x4d50 0x9423 0xbfb 0x4e9f 0x940c 0xc14 0x4fef 0x93f8 0xc35 0x513e 0x93e4 0xc46 0x528e 0x93d0 0xc57 0x53dd 0x93bc 0xc68 0x552d 0x93ae 0xc89 0x567c 0x939d 0xcab 0x57cb 0x9389 0xccd 0x591b 0x9375 0xcee 0x5a6a 0x935d 0xcfd 0x5bba 0x9342 0xcfe 0x5d09 0x9320 0xd0f 0x5e59 0x92ff 0xd33 0x5fa8 0x92dc 0xd62 0x60f8 0x92ad 0xd73 0x6247 0x9282 0xda2 0x6397 0x9258 0xde3 0x64e6 0x9223 0xe16 0x6635 0x91e9 0xe48 0x6785 0x91ad 0xe7e 0x68d4 0x9170 0xed2 0x6a24 0x9123 0xf06 0x6b73 0x90d1 0xf34 0x6cc3 0x90a2 0xfa9 0x6e12 0x9085 0x1036 0x6f62 0x9070 0x10e0 0x70b1 0x905c 0x11ca 0x7201 0x903f 0x12e4 0x7350 0x900c 0x142b 0x749f 0x8f9a 0x15ce 0x75ef 0x8e4a 0x177d 0x773e 0x8c6a 0x19bf 0x788e 0x89c4 0x1ddf 0x79dd 0x85eb 0x2347 0x7b2d 0x8021 0x1b87 0x7c7c 0x7c74 0x1243 0x7dcc 0x7c74 0x1243 0x7f1b 0x7c74 0x1243 0x806b 0x7c74 0x1243 0x81ba 0x7c74 0x1243>;
				battery0_profile_t3_num = <0x64>;
				battery0_profile_t4 = <0x0 0xa62c 0x22f6 0x14f 0xa55c 0x236b 0x29f 0xa471 0x240c 0x3ee 0xa36c 0x24d9 0x53e 0xa283 0x2674 0x68d 0xa1c2 0x27db 0x7dd 0xa124 0x290a 0x92c 0xa0b2 0x295e 0xa7c 0xa044 0x29a8 0xbcb 0x9fd9 0x29ec 0xd1b 0x9f6d 0x2a40 0xe6a 0x9ef0 0x2a58 0xfb9 0x9e64 0x2a3e 0x1109 0x9dc3 0x29ea 0x1258 0x9d22 0x29a1 0x13a8 0x9c84 0x2963 0x14f7 0x9bf7 0x2941 0x1647 0x9b7c 0x2936 0x1796 0x9b0b 0x2936 0x18e6 0x9a9d 0x2936 0x1a35 0x9a31 0x2912 0x1b85 0x99c8 0x28e7 0x1cd4 0x9963 0x28d6 0x1e23 0x9903 0x28ad 0x1f73 0x98a5 0x2887 0x20c2 0x9847 0x2887 0x2212 0x97f2 0x286d 0x2361 0x97a5 0x285f 0x24b1 0x9761 0x2880 0x2600 0x971e 0x287a 0x2750 0x96db 0x286e 0x289f 0x9698 0x286e 0x29ef 0x9660 0x2889 0x2b3e 0x9628 0x28a6 0x2c8d 0x95ec 0x28b6 0x2ddd 0x95c5 0x28f2 0x2f2c 0x959c 0x2923 0x307c 0x9566 0x2934 0x31cb 0x9536 0x2945 0x331b 0x950a 0x295c 0x346a 0x94e2 0x297e 0x35ba 0x94c6 0x29cd 0x3709 0x94ab 0x2a1a 0x3859 0x948f 0x2a5f 0x39a8 0x947b 0x2ac2 0x3af7 0x9464 0x2b17 0x3c47 0x9449 0x2b5a 0x3d96 0x9434 0x2bbe 0x3ee6 0x9420 0x2c23 0x4035 0x940c 0x2c87 0x4185 0x93f8 0x2d10 0x42d4 0x93e0 0x2d8e 0x4424 0x93c5 0x2e03 0x4573 0x93a3 0x2e68 0x46c3 0x9385 0x2ee8 0x4812 0x936a 0x2f7d 0x4961 0x9348 0x2ff2 0x4ab1 0x931f 0x307d 0x4c00 0x92ef 0x3116 0x4d50 0x92c0 0x31ad 0x4e9f 0x9291 0x324f 0x4fef 0x9261 0x32fb 0x513e 0x922b 0x33c4 0x528e 0x91f2 0x348d 0x53dd 0x91b3 0x3555 0x552d 0x9168 0x3611 0x567c 0x911d 0x36cb 0x57cb 0x90d9 0x3790 0x591b 0x90aa 0x388c 0x5a6a 0x9084 0x3987 0x5bba 0x9064 0x3a86 0x5d09 0x9049 0x3b93 0x5e59 0x901f 0x3cd5 0x5fa8 0x8fd0 0x3e1c 0x60f8 0x8f28 0x3f39 0x6247 0x8def 0x3da8 0x6397 0x8be8 0x38d8 0x64e6 0x890a 0x31bb 0x6635 0x84fb 0x27ae 0x6785 0x8278 0x214d 0x68d4 0x8278 0x214d 0x6a24 0x8278 0x214d 0x6b73 0x8278 0x214d 0x6cc3 0x8278 0x214d 0x6e12 0x8278 0x214d 0x6f62 0x8278 0x214d 0x70b1 0x8278 0x214d 0x7201 0x8278 0x214d 0x7350 0x8278 0x214d 0x749f 0x8278 0x214d 0x75ef 0x8278 0x214d 0x773e 0x8278 0x214d 0x788e 0x8278 0x214d 0x79dd 0x8278 0x214d 0x7b2d 0x8278 0x214d 0x7c7c 0x8278 0x214d 0x7dcc 0x8278 0x214d 0x7f1b 0x8278 0x214d 0x806b 0x8278 0x214d 0x81ba 0x8278 0x214d>;
				battery0_profile_t4_num = <0x64>;
				battery1_profile_t0 = <0x0 0xa9c4 0x339 0x14e 0xa93e 0x3bf 0x29c 0xa8c3 0x409 0x3ea 0xa851 0x41a 0x539 0xa7e0 0x41a 0x687 0xa76b 0x423 0x7d5 0xa6f2 0x433 0x923 0xa67a 0x422 0xa71 0xa605 0x41a 0xbbf 0xa594 0x41a 0xd0d 0xa522 0x41a 0xe5c 0xa4ad 0x41a 0xfaa 0xa435 0x41a 0x10f8 0xa3c3 0x42b 0x1246 0xa350 0x42a 0x1394 0xa2dd 0x41c 0x14e2 0xa272 0x43e 0x1630 0xa1ff 0x439 0x177f 0xa188 0x41a 0x18cd 0xa11d 0x41a 0x1a1b 0xa0b2 0x424 0x1b69 0xa048 0x433 0x1cb7 0x9fe4 0x433 0x1e05 0x9f7f 0x43d 0x1f53 0x9f1c 0x44f 0x20a2 0x9ebe 0x470 0x21f0 0x9e5d 0x474 0x233e 0x9df9 0x467 0x248c 0x9d9c 0x477 0x25da 0x9d3a 0x47e 0x2728 0x9cd7 0x480 0x2876 0x9c80 0x490 0x29c5 0x9c29 0x497 0x2b13 0x9bd4 0x49b 0x2c61 0x9b8a 0x4bc 0x2daf 0x9b39 0x4c9 0x2efd 0x9ae3 0x4cb 0x304b 0x9a92 0x4dc 0x3199 0x9a42 0x4f7 0x32e8 0x99f0 0x514 0x3436 0x998b 0x514 0x3584 0x990e 0x4e0 0x36d2 0x9884 0x48e 0x3820 0x9809 0x44a 0x396e 0x97ab 0x433 0x3abc 0x975e 0x433 0x3c0b 0x9722 0x433 0x3d59 0x96e6 0x428 0x3ea7 0x96a9 0x41a 0x3ff5 0x966d 0x41a 0x4143 0x9636 0x41a 0x4291 0x9601 0x41d 0x43df 0x95d3 0x42e 0x452d 0x95a4 0x428 0x467c 0x9575 0x41a 0x47ca 0x9546 0x41a 0x4918 0x951c 0x426 0x4a66 0x94f4 0x433 0x4bb4 0x94cc 0x433 0x4d02 0x94a9 0x43f 0x4e50 0x9487 0x449 0x4f9f 0x9466 0x438 0x50ed 0x9449 0x457 0x523b 0x942c 0x47e 0x5389 0x940a 0x47e 0x54d7 0x93ee 0x47e 0x5625 0x93d3 0x482 0x5773 0x93b9 0x493 0x58c2 0x9399 0x497 0x5a10 0x936b 0x486 0x5b5e 0x931b 0x443 0x5cac 0x92d5 0x426 0x5dfa 0x9299 0x41e 0x5f48 0x9271 0x42f 0x6096 0x9244 0x433 0x61e5 0x9215 0x42e 0x6333 0x91e7 0x41e 0x6481 0x91c2 0x427 0x65cf 0x91a0 0x438 0x671d 0x917e 0x449 0x686b 0x9157 0x44c 0x69b9 0x9129 0x447 0x6b08 0x90ed 0x436 0x6c56 0x90b1 0x425 0x6da4 0x9079 0x42a 0x6ef2 0x904a 0x45c 0x7040 0x9000 0x43c 0x718e 0x8fc3 0x420 0x72dc 0x8faf 0x430 0x742b 0x8fa1 0x441 0x7579 0x8f96 0x45d 0x76c7 0x8f8f 0x48f 0x7815 0x8f67 0x4cf 0x7963 0x8ef0 0x4d8 0x7ab1 0x8df3 0x474 0x7bff 0x8c3a 0x49e 0x7d4e 0x89f9 0x4db 0x7e9c 0x86fe 0x50e 0x7fea 0x8149 0x63c 0x8138 0x771a 0x514>;
				battery1_profile_t0_num = <0x64>;
				battery1_profile_t1 = <0x0 0xa9b0 0x47e 0x14e 0xa92a 0x525 0x29c 0xa8ab 0x578 0x3ea 0xa833 0x578 0x539 0xa7b8 0x578 0x687 0xa743 0x578 0x7d5 0xa6d1 0x579 0x923 0xa65f 0x59b 0xa71 0xa5ea 0x5aa 0xbbf 0xa572 0x5aa 0xd0d 0xa501 0x5aa 0xe5c 0xa48e 0x5a1 0xfaa 0xa419 0x591 0x10f8 0xa3a1 0x591 0x1246 0xa331 0x59b 0x1394 0xa2c5 0x5aa 0x14e2 0xa253 0x5aa 0x1630 0xa1e6 0x5aa 0x177f 0xa17b 0x5ac 0x18cd 0xa10e 0x5bd 0x1a1b 0xa09e 0x5c3 0x1b69 0xa02e 0x5c3 0x1cb7 0x9fca 0x5c3 0x1e05 0x9f6a 0x5ce 0x1f53 0x9f0c 0x5de 0x20a2 0x9eaf 0x5ef 0x21f0 0x9e4b 0x60b 0x233e 0x9de4 0x627 0x248c 0x9d79 0x627 0x25da 0x9d0e 0x633 0x2728 0x9ca6 0x640 0x2876 0x9c48 0x640 0x29c5 0x9bf0 0x657 0x2b13 0x9b9b 0x679 0x2c61 0x9b52 0x69a 0x2daf 0x9b0c 0x6b0 0x2efd 0x9ac3 0x6c1 0x304b 0x9a6d 0x6d2 0x3199 0x9a07 0x6b1 0x32e8 0x9997 0x677 0x3436 0x9918 0x623 0x3584 0x9899 0x5d0 0x36d2 0x9824 0x588 0x3820 0x97cb 0x566 0x396e 0x9779 0x545 0x3abc 0x972f 0x532 0x3c0b 0x96f3 0x543 0x3d59 0x96bc 0x546 0x3ea7 0x9686 0x541 0x3ff5 0x9651 0x530 0x4143 0x961a 0x52d 0x4291 0x95e9 0x538 0x43df 0x95c1 0x55a 0x452d 0x9593 0x55f 0x467c 0x9566 0x55f 0x47ca 0x953e 0x55f 0x4918 0x951c 0x56d 0x4a66 0x94f8 0x572 0x4bb4 0x94cf 0x561 0x4d02 0x94ad 0x56e 0x4e50 0x948e 0x585 0x4f9f 0x9473 0x5a6 0x50ed 0x9452 0x5aa 0x523b 0x9434 0x5aa 0x5389 0x9419 0x5aa 0x54d7 0x93fe 0x5b9 0x5625 0x93e0 0x5bc 0x5773 0x93be 0x5ab 0x58c2 0x93a3 0x5aa 0x5a10 0x9383 0x5a3 0x5b5e 0x935a 0x592 0x5cac 0x9332 0x581 0x5dfa 0x930a 0x570 0x5f48 0x92e1 0x55f 0x6096 0x92b9 0x55f 0x61e5 0x9294 0x55f 0x6333 0x9273 0x55f 0x6481 0x9251 0x55f 0x65cf 0x922c 0x567 0x671d 0x9204 0x578 0x686b 0x91d5 0x578 0x69b9 0x919b 0x578 0x6b08 0x9159 0x578 0x6c56 0x912a 0x589 0x6da4 0x90ed 0x59a 0x6ef2 0x90a4 0x5a9 0x7040 0x9068 0x587 0x718e 0x9045 0x58a 0x72dc 0x9037 0x5ab 0x742b 0x902a 0x5bc 0x7579 0x901c 0x5f3 0x76c7 0x9009 0x644 0x7815 0x8fb2 0x676 0x7963 0x8eac 0x66e 0x7ab1 0x8d15 0x647 0x7bff 0x8ab5 0x69b 0x7d4e 0x8743 0x768 0x7e9c 0x8280 0x9a2 0x7fea 0x79e7 0xc06 0x8138 0x79ae 0xbd1>;
				battery1_profile_t1_num = <0x64>;
				battery1_profile_t2 = <0x0 0xa92e 0x8b1 0x14e 0xa887 0xa53 0x29c 0xa7f1 0xb22 0x3ea 0xa76b 0xb22 0x539 0xa6f3 0xb22 0x687 0xa679 0xb22 0x7d5 0xa5ff 0xb22 0x923 0xa586 0xb22 0xa71 0xa512 0xb22 0xbbf 0xa4a0 0xb21 0xd0d 0xa42f 0xb10 0xe5c 0xa3bd 0xb12 0xfaa 0xa34c 0xb22 0x10f8 0xa2e1 0xb22 0x1246 0xa272 0xb2b 0x1394 0xa201 0xb3b 0x14e2 0xa196 0xb3b 0x1630 0xa12b 0xb3b 0x177f 0xa0c1 0xb3c 0x18cd 0xa05c 0xb4d 0x1a1b 0x9ff8 0xb54 0x1b69 0x9f94 0xb59 0x1cb7 0x9f37 0xb9c 0x1e05 0x9edd 0xbd5 0x1f53 0x9e83 0xc02 0x20a2 0x9e0b 0xbf1 0x21f0 0x9d89 0xbe0 0x233e 0x9d03 0xbd1 0x248c 0x9c8b 0xbd1 0x25da 0x9c23 0xbd1 0x2728 0x9bc9 0xbd5 0x2876 0x9b86 0xbf7 0x29c5 0x9b3f 0xc03 0x2b13 0x9af6 0xc05 0x2c61 0x9aac 0xc16 0x2daf 0x9a5a 0xc07 0x2efd 0x99ff 0xbe0 0x304b 0x998e 0xb9d 0x3199 0x991c 0xb50 0x32e8 0x98ac 0xb01 0x3436 0x9841 0xacf 0x3584 0x97da 0xa9d 0x36d2 0x977b 0xa73 0x3820 0x9738 0xa73 0x396e 0x96f6 0xa68 0x3abc 0x96b4 0xa5a 0x3c0b 0x9678 0xa5a 0x3d59 0x9645 0xa65 0x3ea7 0x9615 0xa73 0x3ff5 0x95df 0xa73 0x4143 0x95ae 0xa73 0x4291 0x957f 0xa7a 0x43df 0x9557 0xa9c 0x452d 0x952f 0xab1 0x467c 0x9507 0xabe 0x47ca 0x94df 0xabe 0x4918 0x94b7 0xabe 0x4a66 0x9492 0xac6 0x4bb4 0x9477 0xae7 0x4d02 0x9458 0xaf0 0x4e50 0x9439 0xafc 0x4f9f 0x9425 0xb2e 0x50ed 0x940c 0xb47 0x523b 0x93f2 0xb58 0x5389 0x93d7 0xb69 0x54d7 0x93c1 0xb79 0x5625 0x93ad 0xb8a 0x5773 0x9399 0xb9b 0x58c2 0x938a 0xbc5 0x5a10 0x9377 0xbee 0x5b5e 0x9356 0xbff 0x5cac 0x9335 0xc10 0x5dfa 0x9313 0xc25 0x5f48 0x92f2 0xc46 0x6096 0x92cb 0xc68 0x61e5 0x92a5 0xc8e 0x6333 0x9284 0xcc0 0x6481 0x925d 0xd0c 0x65cf 0x922d 0xd51 0x671d 0x91eb 0xd73 0x686b 0x91b2 0xdae 0x69b9 0x917a 0xe00 0x6b08 0x913d 0xe77 0x6c56 0x90f0 0xed1 0x6da4 0x90a7 0xf2a 0x6ef2 0x906a 0xf8f 0x7040 0x904f 0x1038 0x718e 0x903b 0x1100 0x72dc 0x9027 0x11ea 0x742b 0x9008 0x131a 0x7579 0x8fd5 0x147f 0x76c7 0x8f7e 0x1631 0x7815 0x8e2a 0x17ab 0x7963 0x8c4f 0x19a5 0x7ab1 0x89cd 0x1ca5 0x7bff 0x85e8 0x219d 0x7d4e 0x8090 0x1cbb 0x7e9c 0x7a62 0xd61 0x7fea 0x7a62 0xd61 0x8138 0x7a62 0xd61>;
				battery1_profile_t2_num = <0x64>;
				battery1_profile_t3 = <0x0 0xa73a 0xf23 0x14e 0xa643 0xfa9 0x29c 0xa57e 0x102e 0x3ea 0xa4eb 0x10b3 0x539 0xa46c 0x10e5 0x687 0xa3f4 0x1120 0x7d5 0xa382 0x1162 0x923 0xa30a 0x1173 0xa71 0xa299 0x1195 0xbbf 0xa22e 0x11c6 0xd0d 0xa1bc 0x11d7 0xe5c 0xa14e 0x11f1 0xfaa 0xa0e3 0x1211 0x10f8 0xa078 0x1222 0x1246 0xa013 0x1245 0x1394 0x9fb4 0x127c 0x14e2 0x9f5d 0x12e0 0x1630 0x9f06 0x1331 0x177f 0x9eac 0x136d 0x18cd 0x9e27 0x134b 0x1a1b 0x9d95 0x1320 0x1b69 0x9cfd 0x12f2 0x1cb7 0x9c78 0x12f2 0x1e05 0x9c05 0x12fc 0x1f53 0x9ba4 0x1311 0x20a2 0x9b61 0x1354 0x21f0 0x9b1a 0x1379 0x233e 0x9ad0 0x1388 0x248c 0x9a8d 0x1388 0x25da 0x9a3d 0x137d 0x2728 0x99e6 0x136d 0x2876 0x9988 0x135c 0x29c5 0x991e 0x1321 0x2b13 0x98ac 0x12d0 0x2c61 0x983b 0x128d 0x2daf 0x97d6 0x1255 0x2efd 0x977a 0x122a 0x304b 0x972a 0x122a 0x3199 0x96e3 0x122a 0x32e8 0x96a1 0x122d 0x3436 0x9665 0x123d 0x3584 0x962d 0x124e 0x36d2 0x95f8 0x125f 0x3820 0x95ca 0x126f 0x396e 0x9596 0x128c 0x3abc 0x9562 0x12a7 0x3c0b 0x953a 0x12a7 0x3d59 0x9512 0x12be 0x3ea7 0x94ea 0x12e3 0x3ff5 0x94c2 0x1315 0x4143 0x949e 0x133c 0x4291 0x947d 0x135d 0x43df 0x945b 0x137f 0x452d 0x943a 0x1394 0x467c 0x941c 0x13b0 0x47ca 0x9408 0x13f3 0x4918 0x93f8 0x1429 0x4a66 0x93eb 0x1463 0x4bb4 0x93de 0x14b7 0x4d02 0x93cb 0x14fe 0x4e50 0x93ba 0x1545 0x4f9f 0x93b4 0x1598 0x50ed 0x93a3 0x15df 0x523b 0x938f 0x162a 0x5389 0x937b 0x168f 0x54d7 0x9362 0x16e6 0x5625 0x9347 0x173e 0x5773 0x932d 0x17a2 0x58c2 0x9308 0x17fa 0x5a10 0x92e1 0x185a 0x5b5e 0x92c0 0x18e0 0x5cac 0x9294 0x1966 0x5dfa 0x9264 0x19f0 0x5f48 0x922e 0x1a86 0x6096 0x91f4 0x1b29 0x61e5 0x91b8 0x1bd9 0x6333 0x917c 0x1ca2 0x6481 0x913a 0x1d77 0x65cf 0x90f3 0x1e5b 0x671d 0x90a1 0x1f5b 0x686b 0x906c 0x209a 0x69b9 0x9044 0x2218 0x6b08 0x9029 0x23fc 0x6c56 0x900e 0x264e 0x6da4 0x8fe9 0x28ff 0x6ef2 0x8fac 0x2c42 0x7040 0x8f0d 0x3055 0x718e 0x8df8 0x347f 0x72dc 0x8c1e 0x3882 0x742b 0x897c 0x32ef 0x7579 0x85bb 0x29a4 0x76c7 0x7ee8 0x18a7 0x7815 0x7de6 0x162b 0x7963 0x7de6 0x162b 0x7ab1 0x7de6 0x162b 0x7bff 0x7de6 0x162b 0x7d4e 0x7de6 0x162b 0x7e9c 0x7de6 0x162b 0x7fea 0x7de6 0x162b 0x8138 0x7de6 0x162b>;
				battery1_profile_t3_num = <0x64>;
				battery1_profile_t4 = <0x0 0xa640 0x22f6 0x14e 0xa57e 0x24a8 0x29c 0xa497 0x25c3 0x3ea 0xa38c 0x264b 0x539 0xa26d 0x27a9 0x687 0xa18b 0x2955 0x7d5 0xa0e4 0x2b45 0x923 0xa073 0x2bcb 0xa71 0xa005 0x2c2e 0xbbf 0x9f99 0x2c6f 0xd0d 0x9f21 0x2c80 0xe5c 0x9e99 0x2c6d 0xfaa 0x9e03 0x2c39 0x10f8 0x9d62 0x2bf6 0x1246 0x9cbe 0x2baa 0x1394 0x9c18 0x2b56 0x14e2 0x9b85 0x2b03 0x1630 0x9afe 0x2ac2 0x177f 0x9a80 0x2a92 0x18cd 0x9a0e 0x2a70 0x1a1b 0x99a8 0x2a6c 0x1b69 0x994c 0x2a7a 0x1cb7 0x98fb 0x2a69 0x1e05 0x98a7 0x2a62 0x1f53 0x9852 0x2a5f 0x20a2 0x9808 0x2a3e 0x21f0 0x97c2 0x2a3a 0x233e 0x9780 0x2a47 0x248c 0x973b 0x2a36 0x25da 0x9700 0x2a45 0x2728 0x96ca 0x2a69 0x2876 0x968e 0x2a9b 0x29c5 0x9656 0x2aad 0x2b13 0x9620 0x2aad 0x2c61 0x95e3 0x2aad 0x2daf 0x95b0 0x2ac2 0x2efd 0x9582 0x2ae1 0x304b 0x955a 0x2af2 0x3199 0x952e 0x2b03 0x32e8 0x9500 0x2b1b 0x3436 0x94d8 0x2b5e 0x3584 0x94b8 0x2b96 0x36d2 0x949d 0x2bcd 0x3820 0x947b 0x2c21 0x396e 0x945e 0x2c75 0x3abc 0x9442 0x2cc8 0x3c0b 0x9421 0x2d1c 0x3d59 0x9404 0x2d6f 0x3ea7 0x93ea 0x2dc9 0x3ff5 0x93d6 0x2e3e 0x4143 0x93b9 0x2ec0 0x4291 0x9395 0x2f47 0x43df 0x936d 0x2fcd 0x452d 0x9345 0x303b 0x467c 0x931c 0x309f 0x47ca 0x92ed 0x3103 0x4918 0x92be 0x3174 0x4a66 0x928e 0x31f4 0x4bb4 0x9258 0x329b 0x4d02 0x9219 0x3336 0x4e50 0x91d6 0x33d0 0x4f9f 0x9193 0x3477 0x50ed 0x914c 0x3512 0x523b 0x9107 0x35b5 0x5389 0x90d2 0x367d 0x54d7 0x90ab 0x375e 0x5625 0x9088 0x384c 0x5773 0x9060 0x3947 0x58c2 0x9038 0x3a81 0x5a10 0x8ff9 0x3bb5 0x5b5e 0x8f7a 0x3c9f 0x5cac 0x8e64 0x3d1e 0x5dfa 0x8cd2 0x3b39 0x5f48 0x8a73 0x353c 0x6096 0x8715 0x2cd5 0x61e5 0x8214 0x2085 0x6333 0x8214 0x2085 0x6481 0x8214 0x2085 0x65cf 0x8214 0x2085 0x671d 0x8214 0x2085 0x686b 0x8214 0x2085 0x69b9 0x8214 0x2085 0x6b08 0x8214 0x2085 0x6c56 0x8214 0x2085 0x6da4 0x8214 0x2085 0x6ef2 0x8214 0x2085 0x7040 0x8214 0x2085 0x718e 0x8214 0x2085 0x72dc 0x8214 0x2085 0x742b 0x8214 0x2085 0x7579 0x8214 0x2085 0x76c7 0x8214 0x2085 0x7815 0x8214 0x2085 0x7963 0x8214 0x2085 0x7ab1 0x8214 0x2085 0x7bff 0x8214 0x2085 0x7d4e 0x8214 0x2085 0x7e9c 0x8214 0x2085 0x7fea 0x8214 0x2085 0x8138 0x8214 0x2085>;
				battery1_profile_t4_num = <0x64>;
				battery2_profile_t0 = <0x0 0xa974 0x339 0x14a 0xa904 0x3cd 0x294 0xa894 0x41a 0x3dd 0xa824 0x41a 0x527 0xa7ad 0x41a 0x671 0xa736 0x413 0x7bb 0xa6c0 0x402 0x905 0xa64f 0x401 0xa4e 0xa5e2 0x40f 0xb98 0xa578 0x430 0xce2 0xa503 0x424 0xe2c 0xa48f 0x41a 0xf76 0xa41e 0x41a 0x10bf 0xa3ae 0x41a 0x1209 0xa341 0x420 0x1353 0xa2d7 0x430 0x149d 0xa268 0x433 0x15e7 0xa1fa 0x433 0x1730 0xa190 0x433 0x187a 0xa122 0x426 0x19c4 0xa0b7 0x424 0x1b0e 0xa05b 0x445 0x1c58 0x9fef 0x43f 0x1da1 0x9f82 0x437 0x1eeb 0x9f1f 0x448 0x2035 0x9ebd 0x44c 0x217f 0x9e5d 0x450 0x22c9 0x9e07 0x460 0x2412 0x9da3 0x465 0x255c 0x9d3d 0x46b 0x26a6 0x9ce8 0x48c 0x27f0 0x9c92 0x497 0x293a 0x9c3c 0x49a 0x2a83 0x9be6 0x4aa 0x2bcd 0x9b91 0x4b0 0x2d17 0x9b3d 0x4b9 0x2e61 0x9af4 0x4fb 0x2fab 0x9a9b 0x50a 0x30f4 0x9a37 0x4f8 0x323e 0x99c7 0x4d7 0x3388 0x994b 0x4a3 0x34d2 0x98c9 0x461 0x361c 0x9858 0x41f 0x3765 0x97fe 0x401 0x38af 0x97b6 0x401 0x39f9 0x9774 0x401 0x3b43 0x9735 0x401 0x3c8d 0x96fa 0x401 0x3dd6 0x96bf 0x412 0x3f20 0x9686 0x41a 0x406a 0x9652 0x41a 0x41b4 0x9623 0x41a 0x42fd 0x95f2 0x41a 0x4447 0x95bd 0x41a 0x4591 0x958f 0x41a 0x46db 0x9563 0x421 0x4825 0x953c 0x431 0x496e 0x951a 0x442 0x4ab8 0x94f4 0x446 0x4c02 0x94c6 0x435 0x4d4c 0x94a3 0x450 0x4e96 0x9480 0x45f 0x4fdf 0x9458 0x44f 0x5129 0x943b 0x45a 0x5273 0x9421 0x471 0x53bd 0x9406 0x492 0x5507 0x93e6 0x497 0x5650 0x93bf 0x48c 0x579a 0x938a 0x46b 0x58e4 0x9345 0x44a 0x5a2e 0x92ff 0x42e 0x5b78 0x92bd 0x41e 0x5cc1 0x928a 0x41a 0x5e0b 0x925e 0x41e 0x5f55 0x9236 0x42f 0x609f 0x920a 0x427 0x61e9 0x91dd 0x41a 0x6332 0x91b5 0x41a 0x647c 0x9193 0x426 0x65c6 0x9170 0x433 0x6710 0x9149 0x433 0x685a 0x910f 0x428 0x69a3 0x90cf 0x41a 0x6aed 0x909b 0x41a 0x6c37 0x9062 0x425 0x6d81 0x9024 0x42d 0x6ecb 0x8fd5 0x3fb 0x7014 0x8fae 0x3f2 0x715e 0x8fa1 0x404 0x72a8 0x8f9b 0x425 0x73f2 0x8f90 0x450 0x753c 0x8f81 0x480 0x7685 0x8f4c 0x4a1 0x77cf 0x8e9f 0x495 0x7919 0x8d8a 0x467 0x7a63 0x8ba8 0x498 0x7bad 0x893e 0x4ec 0x7cf6 0x8654 0x560 0x7e40 0x804d 0x814 0x7f8a 0x776a 0x5aa>;
				battery2_profile_t0_num = <0x64>;
				battery2_profile_t1 = <0x0 0xa8c0 0x47e 0x14a 0xa843 0x4f1 0x294 0xa7c5 0x525 0x3dd 0xa748 0x515 0x527 0xa6d5 0x524 0x671 0xa661 0x52d 0x7bb 0xa5ea 0x52d 0x905 0xa57a 0x53d 0xa4e 0xa507 0x53f 0xb98 0xa490 0x52e 0xce2 0xa41f 0x52d 0xe2c 0xa3ae 0x534 0xf76 0xa33c 0x545 0x10bf 0xa2d2 0x555 0x1209 0xa265 0x558 0x1353 0xa1f5 0x548 0x149d 0xa18b 0x555 0x15e7 0xa121 0x565 0x1730 0xa0b8 0x576 0x187a 0xa04d 0x578 0x19c4 0x9fe4 0x57e 0x1b0e 0x9f81 0x58f 0x1c58 0x9f2a 0x591 0x1da1 0x9ed2 0x59d 0x1eeb 0x9e75 0x5be 0x2035 0x9e09 0x5c3 0x217f 0x9d9a 0x5c8 0x22c9 0x9d2e 0x5d9 0x2412 0x9cca 0x5ea 0x255c 0x9c6b 0x5ff 0x26a6 0x9c15 0x620 0x27f0 0x9bc5 0x64f 0x293a 0x9b74 0x66d 0x2a83 0x9b1e 0x65d 0x2bcd 0x9acd 0x666 0x2d17 0x9a77 0x66a 0x2e61 0x9a0b 0x648 0x2fab 0x9992 0x601 0x30f4 0x9915 0x5aa 0x323e 0x9897 0x547 0x3388 0x9837 0x52d 0x34d2 0x97e3 0x522 0x361c 0x9794 0x4f1 0x3765 0x9752 0x4ee 0x38af 0x9715 0x4f7 0x39f9 0x96da 0x4e7 0x3b43 0x96a3 0x4ee 0x3c8d 0x966e 0x4fb 0x3dd6 0x963a 0x4fb 0x3f20 0x9609 0x4fb 0x406a 0x95db 0x4fe 0x41b4 0x95ac 0x50e 0x42fd 0x9582 0x51f 0x4447 0x955a 0x52d 0x4591 0x9533 0x52d 0x46db 0x950f 0x537 0x4825 0x94ed 0x546 0x496e 0x94c6 0x546 0x4ab8 0x94a6 0x55a 0x4c02 0x948a 0x578 0x4d4c 0x9469 0x578 0x4e96 0x944c 0x582 0x4fdf 0x9431 0x590 0x5129 0x9410 0x57f 0x5273 0x93ef 0x578 0x53bd 0x93ce 0x577 0x5507 0x93ad 0x566 0x5650 0x9388 0x556 0x579a 0x9360 0x544 0x58e4 0x9332 0x523 0x5a2e 0x9303 0x514 0x5b78 0x92d5 0x514 0x5cc1 0x92b4 0x514 0x5e0b 0x9290 0x514 0x5f55 0x9268 0x514 0x609f 0x924d 0x525 0x61e9 0x922c 0x52d 0x6332 0x9205 0x52d 0x647c 0x91d0 0x52d 0x65c6 0x9198 0x52d 0x6710 0x915d 0x52d 0x685a 0x912d 0x53d 0x69a3 0x90f2 0x54e 0x6aed 0x90aa 0x55e 0x6c37 0x906e 0x540 0x6d81 0x9046 0x53b 0x6ecb 0x9039 0x55c 0x7014 0x902c 0x57d 0x715e 0x901c 0x5ac 0x72a8 0x9008 0x5ef 0x73f2 0x8fca 0x613 0x753c 0x8f1e 0x620 0x7685 0x8dd5 0x610 0x77cf 0x8bbf 0x657 0x7919 0x8909 0x6ce 0x7a63 0x856e 0x783 0x7bad 0x7e0c 0xecd 0x7cf6 0x7896 0x92e 0x7e40 0x7896 0x92e 0x7f8a 0x7896 0x92e>;
				battery2_profile_t1_num = <0x64>;
				battery2_profile_t2 = <0x0 0xa79e 0x8b1 0x14a 0xa70d 0x9fb 0x294 0xa682 0xac5 0x3dd 0xa5fe 0xb07 0x527 0xa585 0xb2a 0x671 0xa510 0xb43 0x7bb 0xa4a0 0xb53 0x905 0xa429 0xb54 0xa4e 0xa3b6 0xb63 0xb98 0xa345 0xb84 0xce2 0xa2d5 0xb86 0xe2c 0xa267 0xb8d 0xf76 0xa1fb 0xb9e 0x10bf 0xa18b 0xb90 0x1209 0xa11e 0xb8d 0x1353 0xa0b5 0xb9d 0x149d 0xa04b 0xbae 0x15e7 0x9fe7 0xbbe 0x1730 0x9f8a 0xbcf 0x187a 0x9f38 0xc0b 0x19c4 0x9ee3 0xc48 0x1b0e 0x9e86 0xc79 0x1c58 0x9e08 0xc55 0x1da1 0x9d84 0xc35 0x1eeb 0x9d00 0xc35 0x2035 0x9c8d 0xc35 0x217f 0x9c26 0xc40 0x22c9 0x9bd6 0xc61 0x2412 0x9b91 0xc90 0x255c 0x9b49 0xcad 0x26a6 0x9af3 0xc9c 0x27f0 0x9aa3 0xc99 0x293a 0x9a4c 0xc90 0x2a83 0x99e3 0xc6f 0x2bcd 0x9965 0xc1b 0x2d17 0x98e5 0xbc4 0x2e61 0x9873 0xb92 0x2fab 0x9816 0xb60 0x30f4 0x97c2 0xb3b 0x323e 0x9773 0xb3b 0x3388 0x972e 0xb2f 0x34d2 0x96ef 0xb26 0x361c 0x96ba 0xb36 0x3765 0x9684 0xb3b 0x38af 0x964d 0xb37 0x39f9 0x9612 0xb27 0x3b43 0x95e4 0xb45 0x3c8d 0x95bc 0xb6d 0x3dd6 0x958d 0xb6d 0x3f20 0x955f 0xb78 0x406a 0x9532 0xb89 0x41b4 0x950a 0xb99 0x42fd 0x94e6 0xbaa 0x4447 0x94c4 0xbb6 0x4591 0x949d 0xba5 0x46db 0x947d 0xbc9 0x4825 0x9462 0xc03 0x496e 0x9441 0xc03 0x4ab8 0x9424 0xc17 0x4c02 0x9409 0xc37 0x4d4c 0x93ef 0xc47 0x4e96 0x93d4 0xc58 0x4fdf 0x93ba 0xc6a 0x5129 0x93a7 0xc8b 0x5273 0x9393 0xcac 0x53bd 0x937e 0xccc 0x5507 0x935d 0xcdd 0x5650 0x933b 0xced 0x579a 0x931a 0xcff 0x58e4 0x92f2 0xd20 0x5a2e 0x92ce 0xd49 0x5b78 0x92ad 0xd7b 0x5cc1 0x9286 0xd9c 0x5e0b 0x925e 0xdd6 0x5f55 0x9235 0xe2a 0x609f 0x91fa 0xe6c 0x61e9 0x91be 0xeb6 0x6332 0x9183 0xf09 0x647c 0x914e 0xf6b 0x65c6 0x910a 0xfd6 0x6710 0x90b4 0x1049 0x685a 0x907d 0x10bf 0x69a3 0x9057 0x114b 0x6aed 0x9043 0x11f0 0x6c37 0x902f 0x12d3 0x6d81 0x9016 0x13d7 0x6ecb 0x8ff5 0x14ff 0x7014 0x8f91 0x1674 0x715e 0x8eb5 0x17e5 0x72a8 0x8d2f 0x1946 0x73f2 0x8acb 0x1bc0 0x753c 0x87aa 0x1f13 0x7685 0x838d 0x2387 0x77cf 0x79d6 0xc03 0x7919 0x79d6 0xc03 0x7a63 0x79d6 0xc03 0x7bad 0x79d6 0xc03 0x7cf6 0x79d6 0xc03 0x7e40 0x79d6 0xc03 0x7f8a 0x79d6 0xc03>;
				battery2_profile_t2_num = <0x64>;
				battery2_profile_t3 = <0x0 0xa6e0 0xf23 0x14a 0xa627 0xfd8 0x294 0xa585 0x106e 0x3dd 0xa4fa 0x10e1 0x527 0xa483 0x1125 0x671 0xa40e 0x1160 0x7bb 0xa39c 0x1192 0x905 0xa325 0x11b4 0xa4e 0xa2b2 0x11cd 0xb98 0xa241 0x11de 0xce2 0xa1d7 0x11fe 0xe2c 0xa16e 0x121f 0xf76 0xa104 0x1240 0x10bf 0xa099 0x1243 0x1209 0xa034 0x1258 0x1353 0x9fd7 0x1289 0x149d 0x9f87 0x12c9 0x15e7 0x9f33 0x1305 0x1730 0x9ed6 0x1336 0x187a 0x9e5d 0x132f 0x19c4 0x9dd3 0x130c 0x1b0e 0x9d32 0x12c9 0x1c58 0x9caa 0x12c0 0x1da1 0x9c2f 0x12c0 0x1eeb 0x9bc6 0x12c0 0x2035 0x9b78 0x12e9 0x217f 0x9b2f 0x1310 0x22c9 0x9ae6 0x1321 0x2412 0x9a97 0x1324 0x255c 0x9a43 0x1314 0x26a6 0x99e6 0x12e3 0x27f0 0x9985 0x12bf 0x293a 0x991c 0x1286 0x2a83 0x98a6 0x1213 0x2bcd 0x9843 0x11eb 0x2d17 0x97ea 0x11d7 0x2e61 0x9799 0x11b5 0x2fab 0x974e 0x11a0 0x30f4 0x9709 0x1198 0x323e 0x96ce 0x11a9 0x3388 0x9692 0x11b9 0x34d2 0x9659 0x11ca 0x361c 0x9624 0x11da 0x3765 0x95ef 0x11d3 0x38af 0x95bb 0x11cc 0x39f9 0x958c 0x11ee 0x3b43 0x955e 0x11f8 0x3c8d 0x9531 0x11fb 0x3dd6 0x9509 0x120c 0x3f20 0x94e6 0x1232 0x406a 0x94c4 0x125e 0x41b4 0x949c 0x126f 0x42fd 0x9479 0x128a 0x4447 0x9459 0x12ab 0x4591 0x943e 0x12cd 0x46db 0x9427 0x12f8 0x4825 0x9414 0x1326 0x496e 0x9400 0x1336 0x4ab8 0x93f0 0x136f 0x4c02 0x93e2 0x13be 0x4d4c 0x93cf 0x13f0 0x4e96 0x93be 0x142b 0x4fdf 0x93b0 0x146e 0x5129 0x939d 0x14b0 0x5273 0x9385 0x14f2 0x53bd 0x936a 0x1534 0x5507 0x9349 0x1576 0x5650 0x932c 0x15c1 0x579a 0x9311 0x1614 0x58e4 0x92e9 0x1668 0x5a2e 0x92c4 0x16d5 0x5b78 0x92a3 0x1759 0x5cc1 0x926e 0x17bc 0x5e0b 0x9236 0x181f 0x5f55 0x91fb 0x1882 0x609f 0x91c0 0x1925 0x61e9 0x9184 0x19d4 0x6332 0x9147 0x1a8d 0x647c 0x90f2 0x1b32 0x65c6 0x90ab 0x1bf6 0x6710 0x9077 0x1cdd 0x685a 0x905b 0x1e02 0x69a3 0x9041 0x1f48 0x6aed 0x9026 0x20b3 0x6c37 0x9005 0x22bf 0x6d81 0x8fc1 0x2515 0x6ecb 0x8f51 0x27b9 0x7014 0x8ddd 0x2a5d 0x715e 0x8bed 0x2dc9 0x72a8 0x8968 0x3261 0x73f2 0x85a9 0x2960 0x753c 0x7f65 0x198c 0x7685 0x7c6a 0x12d9 0x77cf 0x7c6a 0x12d9 0x7919 0x7c6a 0x12d9 0x7a63 0x7c6a 0x12d9 0x7bad 0x7c6a 0x12d9 0x7cf6 0x7c6a 0x12d9 0x7e40 0x7c6a 0x12d9 0x7f8a 0x7c6a 0x12d9>;
				battery2_profile_t3_num = <0x64>;
				battery2_profile_t4 = <0x0 0xa4ce 0x22f6 0x14a 0xa3d3 0x2946 0x294 0xa2c9 0x2cf8 0x3dd 0xa1ad 0x2ddf 0x527 0xa0fe 0x2f25 0x671 0xa06a 0x2ff8 0x7bb 0x9ff4 0x303a 0x905 0x9f89 0x305d 0xa4e 0x9f14 0x305b 0xb98 0x9e8d 0x3028 0xce2 0x9df0 0x2faa 0xe2c 0x9d52 0x2f2d 0xf76 0x9cb4 0x2eb9 0x10bf 0x9c33 0x2e90 0x1209 0x9bb8 0x2e76 0x1353 0x9b41 0x2e65 0x149d 0x9ad4 0x2e37 0x15e7 0x9a6c 0x2e12 0x1730 0x9a09 0x2e01 0x187a 0x99a0 0x2dc6 0x19c4 0x9939 0x2d7e 0x1b0e 0x98d6 0x2d2c 0x1c58 0x9873 0x2ce7 0x1da1 0x9816 0x2caf 0x1eeb 0x97c5 0x2c8e 0x2035 0x977c 0x2c7a 0x217f 0x9735 0x2c6a 0x22c9 0x96f3 0x2c59 0x2412 0x96b6 0x2c63 0x255c 0x967b 0x2c6a 0x26a6 0x9640 0x2c5a 0x27f0 0x960e 0x2c7d 0x293a 0x95dd 0x2ca1 0x2a83 0x95a8 0x2ca1 0x2bcd 0x957e 0x2cae 0x2d17 0x9554 0x2cbe 0x2e61 0x9526 0x2ccf 0x2fab 0x94fd 0x2ceb 0x30f4 0x94d7 0x2d0c 0x323e 0x94b5 0x2d2e 0x3388 0x9499 0x2d67 0x34d2 0x9480 0x2d21 0x361c 0x946c 0x2af0 0x3765 0x9458 0x2c3a 0x38af 0x9443 0x2e8e 0x39f9 0x9429 0x2ef1 0x3b43 0x9413 0x2f49 0x3c8d 0x9400 0x2fa1 0x3dd6 0x93f3 0x3014 0x3f20 0x93dd 0x3073 0x406a 0x93c3 0x30cb 0x41b4 0x93a8 0x314f 0x42fd 0x938e 0x31d3 0x4447 0x9372 0x3252 0x4591 0x934b 0x32a5 0x46db 0x932b 0x330a 0x4825 0x930f 0x337c 0x496e 0x92da 0x33ce 0x4ab8 0x92a9 0x343b 0x4c02 0x927b 0x34c0 0x4d4c 0x9246 0x3554 0x4e96 0x920e 0x35f1 0x4fdf 0x91d2 0x3696 0x5129 0x918f 0x373e 0x5273 0x914d 0x37dc 0x53bd 0x910b 0x3871 0x5507 0x90c9 0x3915 0x5650 0x9093 0x39da 0x579a 0x906c 0x3ac0 0x58e4 0x9051 0x3bc7 0x5a2e 0x9030 0x3ce7 0x5b78 0x9008 0x3e27 0x5cc1 0x8fa1 0x3f31 0x5e0b 0x8efd 0x3f74 0x5f55 0x8dc7 0x3d79 0x609f 0x8bce 0x38ac 0x61e9 0x8911 0x31f3 0x6332 0x8538 0x2851 0x647c 0x8200 0x20d0 0x65c6 0x8200 0x20d0 0x6710 0x8200 0x20d0 0x685a 0x8200 0x20d0 0x69a3 0x8200 0x20d0 0x6aed 0x8200 0x20d0 0x6c37 0x8200 0x20d0 0x6d81 0x8200 0x20d0 0x6ecb 0x8200 0x20d0 0x7014 0x8200 0x20d0 0x715e 0x8200 0x20d0 0x72a8 0x8200 0x20d0 0x73f2 0x8200 0x20d0 0x753c 0x8200 0x20d0 0x7685 0x8200 0x20d0 0x77cf 0x8200 0x20d0 0x7919 0x8200 0x20d0 0x7a63 0x8200 0x20d0 0x7bad 0x8200 0x20d0 0x7cf6 0x8200 0x20d0 0x7e40 0x8200 0x20d0 0x7f8a 0x8200 0x20d0>;
				battery2_profile_t4_num = <0x64>;
				battery3_profile_t0 = <0x0 0xa9d8 0x339 0x158 0xa93a 0x3a0 0x2b0 0xa8a3 0x3cf 0x409 0xa813 0x3cd 0x561 0xa789 0x3bc 0x6b9 0xa708 0x3b6 0x811 0xa68c 0x3b6 0x96a 0xa60d 0x3b6 0xac2 0xa596 0x3c3 0xc1a 0xa521 0x3cf 0xd72 0xa4ac 0x3cf 0xecb 0xa437 0x3c0 0x1023 0xa3c2 0x3b6 0x117b 0xa34d 0x3b6 0x12d3 0xa2df 0x3b6 0x142c 0xa270 0x3bf 0x1584 0xa203 0x3d0 0x16dc 0xa19b 0x3e1 0x1834 0xa130 0x3de 0x198d 0xa0c2 0x3cf 0x1ae5 0xa054 0x3cf 0x1c3d 0x9fea 0x3c3 0x1d95 0x9f85 0x3ba 0x1eee 0x9f24 0x3cb 0x2046 0x9ec4 0x3cf 0x219e 0x9e65 0x3db 0x22f6 0x9e0a 0x3fe 0x244f 0x9daa 0x401 0x25a7 0x9d46 0x401 0x26ff 0x9cdf 0x401 0x2857 0x9c86 0x412 0x29b0 0x9c34 0x41a 0x2b08 0x9be7 0x41c 0x2c60 0x9b95 0x42d 0x2db8 0x9b42 0x433 0x2f10 0x9af1 0x436 0x3069 0x9aa5 0x448 0x31c1 0x9a54 0x44c 0x3319 0x9a04 0x456 0x3471 0x99b8 0x479 0x35ca 0x9966 0x49b 0x3722 0x990e 0x4a3 0x387a 0x98ae 0x480 0x39d2 0x9847 0x45e 0x3b2b 0x97dd 0x433 0x3c83 0x976f 0x3ff 0x3ddb 0x9716 0x3cc 0x3f33 0x96c8 0x3b6 0x408c 0x9685 0x3b8 0x41e4 0x964e 0x3c9 0x433c 0x9617 0x3c3 0x4494 0x95e1 0x3b6 0x45ed 0x95b1 0x3b6 0x4745 0x9581 0x3a9 0x489d 0x9553 0x3a2 0x49f5 0x952a 0x3b4 0x4b4e 0x9500 0x3b6 0x4ca6 0x94da 0x3bd 0x4dfe 0x94b7 0x3ce 0x4f56 0x9495 0x3e0 0x50af 0x9473 0x3e8 0x5207 0x9450 0x3e9 0x535f 0x9435 0x3fa 0x54b7 0x9415 0x3f7 0x5610 0x93f4 0x3eb 0x5768 0x93d8 0x3fc 0x58c0 0x93c2 0x40d 0x5a18 0x93aa 0x41a 0x5b70 0x9387 0x41a 0x5cc9 0x936a 0x428 0x5e21 0x9341 0x41c 0x5f79 0x92fc 0x3d7 0x60d1 0x92bd 0x3c0 0x622a 0x9285 0x3b6 0x6382 0x9255 0x3b6 0x64da 0x9232 0x3c7 0x6632 0x9208 0x3c6 0x678b 0x91d9 0x3b7 0x68e3 0x91b7 0x3c9 0x6a3b 0x9194 0x3da 0x6b93 0x9170 0x3e5 0x6cec 0x913f 0x3d4 0x6e44 0x9105 0x3cf 0x6f9c 0x90c7 0x3cf 0x70f4 0x9089 0x3cf 0x724d 0x9046 0x3cf 0x73a5 0x8fff 0x3c9 0x74fd 0x8fb3 0x3b8 0x7655 0x8f9f 0x3b6 0x77ae 0x8f95 0x3ce 0x7906 0x8f8e 0x401 0x7a5e 0x8f80 0x435 0x7bb6 0x8f5f 0x45f 0x7d0f 0x8f1b 0x479 0x7e67 0x8e23 0x445 0x7fbf 0x8c82 0x454 0x8117 0x8a4d 0x499 0x8270 0x8736 0x523 0x83c8 0x8180 0x8c5 0x8520 0x7990 0xb6d>;
				battery3_profile_t0_num = <0x64>;
				battery3_profile_t1 = <0x0 0xa942 0x47e 0x158 0xa896 0x5b4 0x2b0 0xa7fd 0x649 0x409 0xa774 0x659 0x561 0xa6f8 0x659 0x6b9 0xa67c 0x64e 0x811 0xa602 0x640 0x96a 0xa58d 0x640 0xac2 0xa518 0x640 0xc1a 0xa4a3 0x640 0xd72 0xa42e 0x640 0xecb 0xa3b9 0x623 0x1023 0xa348 0x615 0x117b 0xa2df 0x626 0x12d3 0xa271 0x637 0x142c 0xa206 0x649 0x1584 0xa19e 0x659 0x16dc 0xa130 0x659 0x1834 0xa0c2 0x64f 0x198d 0xa055 0x643 0x1ae5 0x9fee 0x654 0x1c3d 0x9f90 0x659 0x1d95 0x9f36 0x65d 0x1eee 0x9edd 0x66e 0x2046 0x9e83 0x68d 0x219e 0x9e20 0x69e 0x22f6 0x9da8 0x68d 0x244f 0x9d39 0x68b 0x25a7 0x9cce 0x68b 0x26ff 0x9c67 0x68b 0x2857 0x9c0e 0x67a 0x29b0 0x9bbc 0x67c 0x2b08 0x9b71 0x68d 0x2c60 0x9b2c 0x69e 0x2db8 0x9aec 0x6c6 0x2f10 0x9aac 0x6f2 0x3069 0x9a67 0x704 0x31c1 0x9a1d 0x715 0x3319 0x99d0 0x721 0x3471 0x997d 0x721 0x35ca 0x9925 0x721 0x3722 0x98c0 0x700 0x387a 0x984b 0x6a9 0x39d2 0x97dd 0x664 0x3b2b 0x9775 0x627 0x3c83 0x9716 0x5f4 0x3ddb 0x96ca 0x5d1 0x3f33 0x9686 0x5b9 0x408c 0x9649 0x5aa 0x41e4 0x9612 0x5aa 0x433c 0x95e0 0x5aa 0x4494 0x95b1 0x5aa 0x45ed 0x9588 0x5aa 0x4745 0x955e 0x5aa 0x489d 0x9535 0x5a5 0x49f5 0x950c 0x593 0x4b4e 0x94e2 0x5a0 0x4ca6 0x94be 0x5b1 0x4dfe 0x94a2 0x5c3 0x4f56 0x9480 0x5c3 0x50af 0x9461 0x5c3 0x5207 0x9446 0x5c4 0x535f 0x942a 0x5d6 0x54b7 0x940f 0x5dc 0x5610 0x93f3 0x5dc 0x5768 0x93d8 0x5dc 0x58c0 0x93c1 0x5e9 0x5a18 0x93aa 0x5f5 0x5b70 0x938f 0x5f5 0x5cc9 0x9373 0x5e7 0x5e21 0x9357 0x5d5 0x5f79 0x933c 0x5c4 0x60d1 0x9319 0x5b3 0x622a 0x92f7 0x5aa 0x6382 0x92d4 0x5aa 0x64da 0x92ab 0x5aa 0x6632 0x9282 0x5b4 0x678b 0x9259 0x5c3 0x68e3 0x9237 0x5c3 0x6a3b 0x9214 0x5e6 0x6b93 0x91ed 0x60e 0x6cec 0x91b6 0x60e 0x6e44 0x9174 0x61b 0x6f9c 0x9132 0x62d 0x70f4 0x90f4 0x63e 0x724d 0x90aa 0x65e 0x73a5 0x9064 0x679 0x74fd 0x9026 0x68a 0x7655 0x9017 0x6bd 0x77ae 0x9005 0x6f1 0x7906 0x8ff1 0x729 0x7a5e 0x8fdc 0x7a1 0x7bb6 0x8fa6 0x82f 0x7d0f 0x8f2f 0x8b6 0x7e67 0x8dd7 0x8d9 0x7fbf 0x8bbd 0x969 0x8117 0x88e1 0xa63 0x8270 0x84bd 0xc11 0x83c8 0x7c4d 0x110c 0x8520 0x78a0 0x8fc>;
				battery3_profile_t1_num = <0x64>;
				battery3_profile_t2 = <0x0 0xa83e 0x8b1 0x158 0xa76f 0xb1d 0x2b0 0xa6c3 0xbcd 0x409 0xa634 0xb3c 0x561 0xa5b1 0xc50 0x6b9 0xa532 0xcbd 0x811 0xa4b8 0xcc8 0x96a 0xa443 0xcb7 0xac2 0xa3ce 0xcb2 0xc1a 0xa35b 0xcb7 0xd72 0xa2ec 0xcc8 0xecb 0xa27c 0xccb 0x1023 0xa210 0xcd2 0x117b 0xa1a8 0xce3 0x12d3 0xa13b 0xcc3 0x142c 0xa0cc 0xcb2 0x1584 0xa05f 0xcb2 0x16dc 0x9ff7 0xcb2 0x1834 0x9fa1 0xce6 0x198d 0x9f54 0xd37 0x1ae5 0x9f01 0xd6a 0x1c3d 0x9e9b 0xd7a 0x1d95 0x9e27 0xd65 0x1eee 0x9d9d 0xd0f 0x2046 0x9d19 0xcd4 0x219e 0x9c9d 0xcac 0x22f6 0x9c2f 0xc9b 0x244f 0x9bd9 0xc99 0x25a7 0x9b8c 0xca8 0x26ff 0x9b47 0xcca 0x2857 0x9b09 0xcfe 0x29b0 0x9ac8 0xd1f 0x2b08 0x9a83 0xd2f 0x2c60 0x9a3e 0xd2f 0x2db8 0x99f9 0xd3a 0x2f10 0x99b1 0xd42 0x3069 0x9957 0xd20 0x31c1 0x98f7 0xcf0 0x3319 0x9892 0xcb2 0x3471 0x9823 0xc5c 0x35ca 0x97bb 0xc14 0x3722 0x9759 0xbd6 0x387a 0x9700 0xba2 0x39d2 0x96ad 0xb6f 0x3b2b 0x9664 0xb4c 0x3c83 0x9626 0xb3b 0x3ddb 0x95ef 0xb3b 0x3f33 0x95bc 0xb45 0x408c 0x958c 0xb54 0x41e4 0x955c 0xb54 0x433c 0x952c 0xb54 0x4494 0x94fe 0xb5c 0x45ed 0x94dc 0xb7e 0x4745 0x94b4 0xb86 0x489d 0x948f 0xb86 0x49f5 0x9474 0xb86 0x4b4e 0x9452 0xb95 0x4ca6 0x9433 0xba6 0x4dfe 0x9417 0xbb7 0x4f56 0x9402 0xbd9 0x50af 0x93ea 0xbfc 0x5207 0x93cf 0xc1f 0x535f 0x93c1 0xc41 0x54b7 0x93b3 0xc6f 0x5610 0x93a6 0xca5 0x5768 0x9398 0xcea 0x58c0 0x938a 0xd2f 0x5a18 0x937c 0xd82 0x5b70 0x936e 0xdfa 0x5cc9 0x9355 0xe49 0x5e21 0x933a 0xea0 0x5f79 0x931e 0xf19 0x60d1 0x92f6 0xf82 0x622a 0x92cd 0xff9 0x6382 0x92a4 0x1083 0x64da 0x927a 0x111e 0x6632 0x924d 0x11c2 0x678b 0x921c 0x126e 0x68e3 0x91e5 0x131a 0x6a3b 0x91a9 0x13d2 0x6b93 0x9169 0x148f 0x6cec 0x911d 0x154c 0x6e44 0x90d6 0x1617 0x6f9c 0x9094 0x16ea 0x70f4 0x9056 0x17ca 0x724d 0x9029 0x1901 0x73a5 0x9005 0x1a56 0x74fd 0x8fea 0x1bbf 0x7655 0x8fc0 0x1d71 0x77ae 0x8f7a 0x1f59 0x7906 0x8f11 0x2171 0x7a5e 0x8e27 0x23a9 0x7bb6 0x8c8c 0x2601 0x7d0f 0x8a4c 0x2889 0x7e67 0x86ef 0x2ba8 0x7fbf 0x8151 0x1e6c 0x8117 0x7cba 0x1324 0x8270 0x7cba 0x1324 0x83c8 0x7cba 0x1324 0x8520 0x7cba 0x1324>;
				battery3_profile_t2_num = <0x64>;
				battery3_profile_t3 = <0x0 0xa758 0xf23 0x158 0xa5f9 0x141d 0x2b0 0xa4f8 0x1710 0x409 0xa448 0x1842 0x561 0xa3b4 0x18ab 0x6b9 0xa32c 0x18ce 0x811 0xa2ab 0x18ce 0x96a 0xa22f 0x18ce 0xac2 0xa1b3 0x1903 0xc1a 0xa139 0x1922 0xd72 0xa0c4 0x18ee 0xecb 0xa05b 0x18e7 0x1023 0x9ff9 0x1903 0x117b 0x9fa0 0x1948 0x12d3 0x9f40 0x195b 0x142c 0x9ed4 0x195b 0x1584 0x9e5a 0x1941 0x16dc 0x9dc2 0x18c9 0x1834 0x9d33 0x1866 0x198d 0x9cad 0x1816 0x1ae5 0x9c38 0x17e2 0x1c3d 0x9bdc 0x17ed 0x1d95 0x9b8b 0x180b 0x1eee 0x9b40 0x181c 0x2046 0x9afa 0x183b 0x219e 0x9ab2 0x1857 0x22f6 0x9a67 0x1869 0x244f 0x9a21 0x187a 0x25a7 0x99d9 0x187b 0x26ff 0x998d 0x186a 0x2857 0x9934 0x1859 0x29b0 0x98da 0x1834 0x2b08 0x987f 0x17ff 0x2c60 0x9818 0x17ba 0x2db8 0x97b5 0x1775 0x2f10 0x9754 0x1730 0x3069 0x96f2 0x16ea 0x31c1 0x969c 0x16bf 0x3319 0x9650 0x16a8 0x3471 0x9612 0x16a8 0x35ca 0x95d4 0x16a8 0x3722 0x9599 0x16af 0x387a 0x9562 0x16c0 0x39d2 0x9531 0x16e2 0x3b2b 0x9505 0x16fc 0x3c83 0x94db 0x170d 0x3ddb 0x94b2 0x171e 0x3f33 0x9491 0x174f 0x408c 0x9475 0x178c 0x41e4 0x9452 0x179d 0x433c 0x9439 0x17ba 0x4494 0x9427 0x17f2 0x45ed 0x9419 0x186b 0x4745 0x940b 0x18e3 0x489d 0x93fd 0x1962 0x49f5 0x93ef 0x19eb 0x4b4e 0x93e1 0x1a68 0x4ca6 0x93d4 0x1aea 0x4dfe 0x93c6 0x1b74 0x4f56 0x93b8 0x1c32 0x50af 0x93aa 0x1cef 0x5207 0x939c 0x1db2 0x535f 0x9387 0x1ea3 0x54b7 0x9372 0x1f72 0x5610 0x935c 0x203a 0x5768 0x9341 0x212b 0x58c0 0x9325 0x2229 0x5a18 0x9308 0x232b 0x5b70 0x92e5 0x242d 0x5cc9 0x92b7 0x2521 0x5e21 0x928a 0x2626 0x5f79 0x9260 0x274b 0x60d1 0x922a 0x285f 0x622a 0x91f3 0x296a 0x6382 0x91bb 0x2a6d 0x64da 0x917e 0x2b81 0x6632 0x9140 0x2ca8 0x678b 0x9101 0x2ddc 0x68e3 0x90c2 0x2f07 0x6a3b 0x908e 0x306b 0x6b93 0x905d 0x31d8 0x6cec 0x902d 0x331f 0x6e44 0x9008 0x3482 0x6f9c 0x8fe1 0x35df 0x70f4 0x8fb1 0x3726 0x724d 0x8f42 0x383e 0x73a5 0x8e83 0x3923 0x74fd 0x8d69 0x39d0 0x7655 0x8b44 0x3749 0x77ae 0x8812 0x2f47 0x7906 0x82ff 0x22a4 0x7a5e 0x7e72 0x1757 0x7bb6 0x7e72 0x1757 0x7d0f 0x7e72 0x1757 0x7e67 0x7e72 0x1757 0x7fbf 0x7e72 0x1757 0x8117 0x7e72 0x1757 0x8270 0x7e72 0x1757 0x83c8 0x7e72 0x1757 0x8520 0x7e72 0x1757>;
				battery3_profile_t3_num = <0x64>;
				battery3_profile_t4 = <0x0 0xa636 0x22f6 0x158 0xa530 0x298d 0x2b0 0xa458 0x2cdd 0x409 0xa3a8 0x2d61 0x561 0xa318 0x2d0b 0x6b9 0xa283 0x2c88 0x811 0xa1ef 0x2bdd 0x96a 0xa16c 0x2aec 0xac2 0xa0f4 0x2aad 0xc1a 0xa085 0x2aa3 0xd72 0xa024 0x2a81 0xecb 0x9fbc 0x2a40 0x1023 0x9f48 0x29e6 0x117b 0x9ec6 0x296d 0x12d3 0x9e2f 0x28b3 0x142c 0x9d9f 0x2810 0x1584 0x9d15 0x2787 0x16dc 0x9c92 0x270e 0x1834 0x9c20 0x26d4 0x198d 0x9bbd 0x26bd 0x1ae5 0x9b71 0x268a 0x1c3d 0x9b21 0x2662 0x1d95 0x9ad0 0x2648 0x1eee 0x9a84 0x2648 0x2046 0x9a33 0x2648 0x219e 0x99e0 0x2648 0x22f6 0x998b 0x2648 0x244f 0x992c 0x2629 0x25a7 0x98cc 0x25f6 0x26ff 0x986b 0x25b2 0x2857 0x9819 0x257e 0x29b0 0x97c2 0x2567 0x2b08 0x9769 0x2563 0x2c60 0x9717 0x2541 0x2db8 0x96c4 0x252a 0x2f10 0x9676 0x251f 0x3069 0x9638 0x2531 0x31c1 0x95f9 0x2535 0x3319 0x95bc 0x2535 0x3471 0x9585 0x2535 0x35ca 0x954e 0x2535 0x3722 0x951d 0x2543 0x387a 0x94f3 0x2566 0x39d2 0x94ca 0x2599 0x3b2b 0x94a8 0x25d5 0x3c83 0x948d 0x261d 0x3ddb 0x9478 0x2696 0x3f33 0x9463 0x26f9 0x408c 0x9450 0x274f 0x41e4 0x9442 0x27a5 0x433c 0x9439 0x2822 0x4494 0x942e 0x28bc 0x45ed 0x941a 0x2979 0x4745 0x9405 0x2a0c 0x489d 0x93f5 0x2ac9 0x49f5 0x93ef 0x2bdd 0x4b4e 0x93db 0x2ca1 0x4ca6 0x93c6 0x2d66 0x4dfe 0x93b2 0x2e36 0x4f56 0x93a4 0x2f38 0x50af 0x9392 0x301d 0x5207 0x937e 0x30f5 0x535f 0x9369 0x321a 0x54b7 0x9350 0x32fa 0x5610 0x9334 0x33b0 0x5768 0x9319 0x344b 0x58c0 0x92fd 0x351a 0x5a18 0x92e0 0x35ea 0x5b70 0x92bd 0x3696 0x5cc9 0x9294 0x3727 0x5e21 0x9267 0x37ab 0x5f79 0x9237 0x3824 0x60d1 0x9207 0x388c 0x622a 0x91d3 0x3905 0x6382 0x919c 0x398f 0x64da 0x915e 0x3a18 0x6632 0x911c 0x3a8d 0x678b 0x90d9 0x3b05 0x68e3 0x90a2 0x3bd4 0x6a3b 0x9075 0x3ca2 0x6b93 0x904f 0x3d90 0x6cec 0x9033 0x3ed7 0x6e44 0x9018 0x4071 0x6f9c 0x8fef 0x41d1 0x70f4 0x8fa6 0x4227 0x724d 0x8f0a 0x40b7 0x73a5 0x8da7 0x3d42 0x74fd 0x8b68 0x37c1 0x7655 0x8820 0x2fa8 0x77ae 0x8660 0x2b11 0x7906 0x8660 0x2b11 0x7a5e 0x8660 0x2b11 0x7bb6 0x8660 0x2b11 0x7d0f 0x8660 0x2b11 0x7e67 0x8660 0x2b11 0x7fbf 0x8660 0x2b11 0x8117 0x8660 0x2b11 0x8270 0x8660 0x2b11 0x83c8 0x8660 0x2b11 0x8520 0x8660 0x2b11>;
				battery3_profile_t4_num = <0x64>;
				compatible = "mediatek,bat_gm30";
				g_FG_PSEUDO100_T0 = <0x64>;
				g_FG_PSEUDO100_T1 = <0x64>;
				g_FG_PSEUDO100_T2 = <0x64>;
				g_FG_PSEUDO100_T3 = <0x64>;
				g_FG_PSEUDO100_T4 = <0x64>;
				g_FG_PSEUDO1_T0 = <0x0>;
				g_FG_PSEUDO1_T1 = <0x0>;
				g_FG_PSEUDO1_T2 = <0x0>;
				g_FG_PSEUDO1_T3 = <0x0>;
				g_FG_PSEUDO1_T4 = <0x0>;
				phandle = <0x73>;
			};

			fuelgauge {
				compatible = "mediatek, fuelgauge";
				enabled = <0x1>;
				phandle = <0x82>;
			};

			kpd_volume_down {
				compatible = "mediatek, VOLUME_DOWN-eint";
				debounce = <0x7d00>;
				interrupt-parent = <0xffffffff>;
				interrupts = <0x5e 0x2 0x5e 0x0>;
				phandle = <0x7e>;
				status = "okay";
			};

			kpd_volume_up {
				compatible = "mediatek, VOLUME_UP-eint";
				debounce = <0x7d00>;
				interrupt-parent = <0xffffffff>;
				interrupts = <0x14 0x2 0x14 0x0>;
				phandle = <0x7d>;
				status = "okay";
			};

			led@0 {
				compatible = "mediatek,red";
				data = <0x1>;
				led_mode = <0x0>;
				phandle = <0x74>;
				pwm_config = <0x0 0x0 0x0 0x0 0x0>;
			};

			led@1 {
				compatible = "mediatek,green";
				data = <0x1>;
				led_mode = <0x0>;
				phandle = <0x75>;
				pwm_config = <0x0 0x0 0x0 0x0 0x0>;
			};

			led@2 {
				compatible = "mediatek,blue";
				data = <0x1>;
				led_mode = <0x0>;
				phandle = <0x76>;
				pwm_config = <0x0 0x0 0x0 0x0 0x0>;
			};

			led@3 {
				compatible = "mediatek,jogball-backlight";
				data = <0x1>;
				led_mode = <0x0>;
				phandle = <0x77>;
				pwm_config = <0x0 0x0 0x0 0x0 0x0>;
			};

			led@4 {
				compatible = "mediatek,keyboard-backlight";
				data = <0x1>;
				led_mode = <0x0>;
				phandle = <0x78>;
				pwm_config = <0x0 0x0 0x0 0x0 0x0>;
			};

			led@5 {
				compatible = "mediatek,button-backlight";
				data = <0x1>;
				led_mode = <0x0>;
				phandle = <0x79>;
				pwm_config = <0x0 0x0 0x0 0x0 0x0>;
			};

			led@6 {
				compatible = "mediatek,lcd-backlight";
				data = <0x1>;
				led_mode = <0x4>;
				phandle = <0x7a>;
				pwm_config = <0x0 0x3 0x0 0x0 0x0>;
			};

			oppo_charger {
				compatible = "mediatek,oppo-charger";
				phandle = <0x81>;
				pinctrl-0 = <0x8>;
				pinctrl-1 = <0x9>;
				pinctrl-2 = <0xa>;
				pinctrl-3 = <0xb>;
				pinctrl-4 = <0xc>;
				pinctrl-5 = <0xd>;
				pinctrl-names = "default", "charger_gpio_as_output_low", "charger_gpio_as_output_high", "ship_sleep", "ship_active", "shortc_active";
				qcom,batt_capacity_mah = <0xce4>;
				qcom,charger_hv_thr = <0x16a8>;
				qcom,charger_lv_thr = <0xd48>;
				qcom,chargerid_switch-gpio = <0xffffffff 0x9 0x0>;
				qcom,check_batt_full_by_sw;
				qcom,chg_ctrl_by_calling;
				qcom,chg_ctrl_by_camera;
				qcom,chg_ctrl_by_lcd;
				qcom,cold_bat_decidegc = <0x1e>;
				qcom,cold_vfloat_over_sw_limit = <0xf8c>;
				qcom,cold_vfloat_sw_limit = <0xf5a>;
				qcom,cool_bat_decidegc = <0x32>;
				qcom,cool_vfloat_over_sw_limit = <0x1126>;
				qcom,cool_vfloat_sw_limit = <0x10e0>;
				qcom,default_iterm_ma = <0xac>;
				qcom,default_normal_vfloat_over_sw_limit = <0x1126>;
				qcom,default_normal_vfloat_sw_limit = <0x10ef>;
				qcom,default_temp_normal_fastchg_current_ma = <0x834>;
				qcom,default_temp_normal_vfloat_mv = <0x1121>;
				qcom,ff1_normal_fastchg_ma = <0x400>;
				qcom,ffc2_exit_step_ma = <0x64>;
				qcom,ffc2_normal_fastchg_ma = <0x2c6>;
				qcom,ffc2_temp_high_decidegc = <0x190>;
				qcom,ffc2_temp_low_decidegc = <0xa0>;
				qcom,ffc2_temp_warm_decidegc = <0x15e>;
				qcom,ffc2_warm_fastchg_ma = <0x302>;
				qcom,ffc_normal_vfloat_over_sw_limit = <0x1194>;
				qcom,ffc_normal_vfloat_sw_limit = <0x114e>;
				qcom,ffc_temp_normal_vfloat_mv = <0x1194>;
				qcom,hot_bat_decidegc = <0x212>;
				qcom,input_current_calling_ma = <0x5dc>;
				qcom,input_current_camera_ma = <0x4b0>;
				qcom,input_current_cdp_ma = <0x5dc>;
				qcom,input_current_charger_ma = <0x7d0>;
				qcom,input_current_led_ma = <0x384>;
				qcom,input_current_led_ma_forcmcc = <0x1f4>;
				qcom,input_current_usb_ma = <0x1f4>;
				qcom,iterm_disabled = <0x0>;
				qcom,iterm_ma = <0xa5>;
				qcom,little_cold_bat_decidegc = <0x0>;
				qcom,little_cold_vfloat_over_sw_limit = <0x1126>;
				qcom,little_cold_vfloat_sw_limit = <0x10e0>;
				qcom,little_cool_bat_decidegc = <0x78>;
				qcom,little_cool_vfloat_over_sw_limit = <0x1126>;
				qcom,little_cool_vfloat_sw_limit = <0x10e0>;
				qcom,max_chg_time_sec = <0x8ca0>;
				qcom,non_normal_vterm_hw_inc = <0x12>;
				qcom,non_standard_fastchg_current_ma = <0x200>;
				qcom,non_standard_vfloat_mv = <0xfa0>;
				qcom,non_standard_vfloat_over_sw_limit = <0xf8c>;
				qcom,non_standard_vfloat_sw_limit = <0xf6e>;
				qcom,normal_bat_decidegc = <0xa0>;
				qcom,normal_vfloat_over_sw_limit = <0x1126>;
				qcom,normal_vfloat_sw_limit = <0x10e0>;
				qcom,normal_vterm_hw_inc = <0x12>;
				qcom,recharge-mv = <0x64>;
				qcom,removed_bat_decidegc = <0xbe>;
				qcom,ship-gpio = <0xffffffff 0x98 0x0>;
				qcom,short_c_bat_cv_mv = <0x10ea>;
				qcom,short_c_bat_fastchg_current_ma = <0x200>;
				qcom,short_c_bat_vfloat_mv = <0xed8>;
				qcom,short_c_bat_vfloat_sw_limit = <0xea6>;
				qcom,shortc-gpio = <0xffffffff 0x19 0x0>;
				qcom,sw_vfloat_over_protect_enable;
				qcom,temp_cold_fastchg_current_ma = <0x16c>;
				qcom,temp_cold_vfloat_mv = <0xf8c>;
				qcom,temp_cool_fastchg_current_ma_high = <0x38c>;
				qcom,temp_cool_fastchg_current_ma_low = <0x1cf>;
				qcom,temp_cool_vfloat_mv = <0x1112>;
				qcom,temp_little_cold_fastchg_current_ma = <0x1cf>;
				qcom,temp_little_cold_fastchg_current_ma_high = <0x1cf>;
				qcom,temp_little_cold_fastchg_current_ma_low = <0x1cf>;
				qcom,temp_little_cold_vfloat_mv = <0x1112>;
				qcom,temp_little_cool_fastchg_current_ma = <0x5ad>;
				qcom,temp_little_cool_vfloat_mv = <0x1112>;
				qcom,temp_normal_fastchg_current_ma = <0x7d0>;
				qcom,temp_normal_vfloat_mv = <0x1112>;
				qcom,temp_warm_fastchg_current_ma = <0x38c>;
				qcom,temp_warm_vfloat_mv = <0xff0>;
				qcom,usb_enum_enable;
				qcom,vbatt_full_thr = <0x1130>;
				qcom,vbatt_hv_thr = <0x1194>;
				qcom,vbatt_num = <0x1>;
				qcom,vbatt_power_off = <0xce4>;
				qcom,vbatt_soc_1 = <0xd52>;
				qcom,vfloat_step_mv = <0x10>;
				qcom,vooc_project = <0x0>;
				qcom,warm_bat_decidegc = <0x1c2>;
				qcom,warm_vfloat_over_sw_limit = <0xff0>;
				qcom,warm_vfloat_sw_limit = <0xfbe>;
			};

			oppo_devinfo {
				Hw,main_hwid_5 = <0xffffffff 0x5c 0x0>;
				Hw,main_hwid_6 = <0xffffffff 0xf 0x0>;
				Hw,sub_hwid_1 = <0xffffffff 0xb0 0x0>;
				Hw,sub_hwid_2 = <0xffffffff 0x3a 0x0>;
				compatible = "oppo, device_info";
				phandle = <0x80>;
				pinctrl-0 = <0x1>;
				pinctrl-1 = <0x2 0x3>;
				pinctrl-2 = <0x4 0x5>;
				pinctrl-3 = <0x6>;
				pinctrl-4 = <0x7>;
				pinctrl-names = "default", "hw_sub_id_sleep", "hw_sub_id_active", "hw_main_id5_active", "hw_main_id6_active";
			};

			oppo_project {
				compatible = "oppo,oppo_project";
				phandle = <0x7c>;
			};

			oppo_sensor {
				phandle = <0x7f>;
			};

			vibrator@0 {
				compatible = "mediatek,vibrator";
				phandle = <0x7b>;
				vib_limit = <0x0>;
				vib_timer = <0x1e>;
				vib_vol = <0xb>;
			};
		};
	};

	fragment@10 {
		target = <0xffffffff>;

		__overlay__ {

			eint0default {
				phandle = <0x1e>;
			};

			eint@0 {
				phandle = <0x1f>;

				pins_cmd_dat {
					bias-disable;
					pinmux = <0x100>;
					slew-rate = <0x0>;
				};
			};

			eintoutput0 {
				phandle = <0x20>;

				pins_cmd_dat {
					output-low;
					pinmux = <0x100>;
					slew-rate = <0x1>;
				};
			};

			eintoutput1 {
				phandle = <0x21>;

				pins_cmd_dat {
					output-high;
					pinmux = <0x100>;
					slew-rate = <0x1>;
				};
			};

			rstoutput0 {
				phandle = <0x22>;

				pins_cmd_dat {
					output-low;
					pinmux = <0x200>;
					slew-rate = <0x1>;
				};
			};

			rstoutput1 {
				phandle = <0x23>;

				pins_cmd_dat {
					output-high;
					pinmux = <0x200>;
					slew-rate = <0x1>;
				};
			};
		};
	};

	fragment@11 {
		target = <0xffffffff>;

		__overlay__ {

			bq24190-charger@6b {
				chip-name = "BQ24190";
				compatible = "oppo,bq24190-charger";
				interrupt-parent = <0xffffffff>;
				interrupts = <0x5b 0x2 0x5b 0x0>;
				reg = <0x6b>;
				status = "okay";
			};

			bq25890h-charger@6a {
				chip-name = "BQ25890H";
				compatible = "oppo,bq25890h-charger";
				interrupt-parent = <0xffffffff>;
				interrupts = <0x5b 0x2 0x5b 0x0>;
				reg = <0x6a>;
				status = "okay";
			};
		};
	};

	fragment@12 {
		target = <0xffffffff>;

		__overlay__ {

			charger_gpio_as_output_high {
				phandle = <0xa>;

				pins_cmd_dat {
					output-high;
					pinmux = <0x900>;
					slew-rate = <0x1>;
				};
			};

			charger_gpio_as_output_low {
				phandle = <0x9>;

				pins_cmd_dat {
					output-low;
					pinmux = <0x900>;
					slew-rate = <0x1>;
				};
			};

			eint0default {
				phandle = <0x8>;
			};

			ship_active {
				phandle = <0xc>;

				pins_cmd_dat {
					output-high;
					pinmux = <0x9800>;
					slew-rate = <0x1>;
				};
			};

			ship_sleep {
				phandle = <0xb>;

				pins_cmd_dat {
					output-low;
					pinmux = <0x9800>;
					slew-rate = <0x1>;
				};
			};

			shortc_active {
				phandle = <0xd>;

				pins_cmd_dat {
					bias-pull-up;
					input-enable;
					pinmux = <0x1900>;
					slew-rate = <0x0>;
				};
			};
		};
	};

	fragment@13 {
		target = <0xffffffff>;

		__overlay__ {
			status = "okay";

			dhall0-m1120@0f {
				compatible = "oppo,dhall-m1120";
				dhall,id = <0x0>;
				dhall,irq-gpio = <0xffffffff 0x5 0x2008>;
				hall-power-gpio = <0xffffffff 0x6e 0x0>;
				interrupt-parent = <0xffffffff>;
				interrupts = <0x5 0x8 0x5 0x0>;
				pinctrl-0 = <0x24>;
				pinctrl-1 = <0x25>;
				pinctrl-2 = <0x26>;
				pinctrl-names = "hall_power_down", "hall_power_up", "hall0_interrupt_input";
				reg = <0xf>;
				status = "okay";
			};

			dhall1-m1120@0c {
				compatible = "oppo,dhall-m1120";
				dhall,id = <0x1>;
				dhall,irq-gpio = <0xffffffff 0x6 0x2008>;
				hall-power-gpio = <0xffffffff 0x6e 0x0>;
				interrupt-parent = <0xffffffff>;
				interrupts = <0x6 0x8 0x6 0x0>;
				pinctrl-0 = <0x24>;
				pinctrl-1 = <0x25>;
				pinctrl-2 = <0x27>;
				pinctrl-names = "hall_power_down", "hall_power_up", "hall1_interrupt_input";
				reg = <0xc>;
				status = "okay";
			};
		};
	};

	fragment@14 {
		target = <0xffffffff>;

		__overlay__ {

			hall0_interrupt_input {
				phandle = <0x26>;

				pins_cmd_dat {
					bias-disable;
					drive-strength = <0x2>;
					pinmux = <0x600>;
					slew-rate = <0x0>;
				};
			};

			hall1_interrupt_input {
				phandle = <0x27>;

				pins_cmd_dat {
					bias-disable;
					drive-strength = <0x2>;
					pinmux = <0x500>;
					slew-rate = <0x0>;
				};
			};

			hall_power_down {
				phandle = <0x24>;

				pins_cmd_dat {
					bias-pull-down;
					drive-strength = <0x2>;
					output-low;
					pinmux = <0x6e00>;
					slew-rate = <0x1>;
				};
			};

			hall_power_up {
				phandle = <0x25>;

				pins_cmd_dat {
					bias-pull-down;
					drive-strength = <0x2>;
					output-high;
					pinmux = <0x6e00>;
					slew-rate = <0x1>;
				};
			};
		};
	};

	fragment@15 {
		target = <0xffffffff>;

		__overlay__ {
			compatible = "mediatek,usb_iddig_bi_eint";
			pinctrl-0 = <0x28>;
			pinctrl-1 = <0x29>;
			pinctrl-2 = <0x2a>;
			pinctrl-names = "id_default", "id_init", "id_output_low";
			qcom,otg_switch_gpio = <0x29>;
			status = "okay";
		};
	};

	fragment@16 {
		target = <0xffffffff>;

		__overlay__ {

			id_default {
				phandle = <0x28>;
			};

			id_init {
				phandle = <0x29>;

				pins_cmd_dat {
					bias-pull-up = <0x65>;
					pinmux = <0x2901>;
					slew-rate = <0x0>;
				};
			};

			id_output_low {
				phandle = <0x2a>;

				pins_cmd_dat {
					output-low;
					pinmux = <0x2900>;
					slew-rate = <0x1>;
				};
			};
		};
	};

	fragment@17 {
		target = <0xffffffff>;

		__overlay__ {
			accdet-mic-mode = <0x1>;
			accdet-mic-vol = <0x7>;
			accdet-plugout-debounce = <0x1>;
			headset-eint-level-pol = <0x8>;
			headset-four-key-threshold = <0x0 0x3a 0x79 0xc0 0x190>;
			headset-mode-setting = <0x500 0x500 0x1 0x1f0 0x800 0x800 0x20 0x44>;
			headset-three-key-threshold = <0x0 0x52 0xaa 0x132>;
			headset-three-key-threshold-CDD = <0x0 0x79 0xc0 0x258>;
			status = "okay";
		};
	};

	fragment@18 {
		target = <0xffffffff>;

		__overlay__ {
			pinctrl-0 = <0x2b>;
			pinctrl-1 = <0x2c>;
			pinctrl-10 = <0x35>;
			pinctrl-11 = <0x36>;
			pinctrl-2 = <0x2d>;
			pinctrl-3 = <0x2e>;
			pinctrl-4 = <0x2f>;
			pinctrl-5 = <0x30>;
			pinctrl-6 = <0x31>;
			pinctrl-7 = <0x32>;
			pinctrl-8 = <0x33>;
			pinctrl-9 = <0x34>;
			pinctrl-names = "aud_dat_mosi_off", "aud_dat_mosi_on", "aud_dat_miso_off", "aud_dat_miso_on", "hpamp-pullhigh", "hpamp-pulllow", "aud_clk_mosi_off", "aud_clk_mosi_on", "audi2s0-mode0", "audi2s0-mode1", "audi2s1-mode0", "audi2s1-mode1";
			status = "okay";
		};
	};

	fragment@19 {
		target = <0xffffffff>;

		__overlay__ {

			aud_clk_mosi_off {
				phandle = <0x31>;
			};

			aud_clk_mosi_on {
				phandle = <0x32>;
			};

			aud_dat_miso_off {
				phandle = <0x2d>;
			};

			aud_dat_miso_on {
				phandle = <0x2e>;
			};

			aud_dat_mosi_off {
				phandle = <0x2b>;
			};

			aud_dat_mosi_on {
				phandle = <0x2c>;
			};

			audhpamphigh {
				phandle = <0x2f>;
			};

			audhpamplow {
				phandle = <0x30>;
			};

			audi2s0mode0 {
				phandle = <0x33>;

				pins_cmd_dat {
					pinmux = <0xae00>;
				};
			};

			audi2s0mode1 {
				phandle = <0x34>;

				pins_cmd_dat {
					pinmux = <0xae02>;
				};
			};

			audi2s1mode0 {
				phandle = <0x35>;

				pins_cmd0_dat {
					pinmux = <0xaa00>;
				};

				pins_cmd1_dat {
					pinmux = <0xab00>;
				};

				pins_cmd2_dat {
					pinmux = <0xac00>;
				};
			};

			audi2s1mode1 {
				phandle = <0x36>;

				pins_cmd0_dat {
					pinmux = <0xaa02>;
				};

				pins_cmd1_dat {
					pinmux = <0xab02>;
				};

				pins_cmd2_dat {
					pinmux = <0xac02>;
				};
			};
		};
	};

	fragment@2 {
		target = <0xffffffff>;

		__overlay__ {

			phy_tuning {
				compatible = "mediatek,phy_tuning";
				u2_enhance = <0x2>;
				u2_term_ref = <0x7>;
				u2_vrt_ref = <0x7>;
			};
		};
	};

	fragment@20 {
		target = <0xffffffff>;

		__overlay__ {

			consys_default {
				phandle = <0x37>;
			};

			gpslna@0 {
				phandle = <0x38>;

				pins_cmd_dat {
					bias-disable;
					output-low;
					pinmux = <0xa900>;
					slew-rate = <0x1>;
				};
			};

			gpslna@1 {
				phandle = <0x39>;

				pins_cmd_dat {
					output-high;
					pinmux = <0xa900>;
					slew-rate = <0x1>;
				};
			};

			gpslna@2 {
				phandle = <0x3a>;

				pins_cmd_dat {
					output-low;
					pinmux = <0xa900>;
					slew-rate = <0x1>;
				};
			};
		};
	};

	fragment@21 {
		target = <0xffffffff>;

		__overlay__ {
			pinctrl-0 = <0x37>;
			pinctrl-1 = <0x38>;
			pinctrl-2 = <0x39>;
			pinctrl-3 = <0x3a>;
			pinctrl-names = "default", "gps_lna_state_init", "gps_lna_state_oh", "gps_lna_state_ol";
			status = "okay";
		};
	};

	fragment@22 {
		target = <0xffffffff>;

		__overlay__ {

			cam0@0 {
				phandle = <0x3c>;

				pins_cmd_dat {
					output-low;
					pinmux = <0x6500>;
					slew-rate = <0x1>;
				};
			};

			cam0@1 {
				phandle = <0x3d>;

				pins_cmd_dat {
					output-high;
					pinmux = <0x6500>;
					slew-rate = <0x1>;
				};
			};

			cam0@2 {
				phandle = <0x3e>;

				pins_cmd_dat {
					output-low;
					pinmux = <0x6100>;
					slew-rate = <0x1>;
				};
			};

			cam0@3 {
				phandle = <0x3f>;

				pins_cmd_dat {
					output-high;
					pinmux = <0x6100>;
					slew-rate = <0x1>;
				};
			};

			cam0@vcam0 {
				phandle = <0x48>;

				pins_cmd_dat {
					output-low;
					pinmux = <0x5b00>;
					slew-rate = <0x1>;
				};
			};

			cam0@vcam1 {
				phandle = <0x49>;

				pins_cmd_dat {
					output-high;
					pinmux = <0x5b00>;
					slew-rate = <0x1>;
				};
			};

			cam1@0 {
				phandle = <0x40>;

				pins_cmd_dat {
					output-low;
					pinmux = <0x6600>;
					slew-rate = <0x1>;
				};
			};

			cam1@1 {
				phandle = <0x41>;

				pins_cmd_dat {
					output-high;
					pinmux = <0x6600>;
					slew-rate = <0x1>;
				};
			};

			cam1@2 {
				phandle = <0x42>;

				pins_cmd_dat {
					output-low;
					pinmux = <0x6200>;
					slew-rate = <0x1>;
				};
			};

			cam1@3 {
				phandle = <0x43>;

				pins_cmd_dat {
					output-high;
					pinmux = <0x6200>;
					slew-rate = <0x1>;
				};
			};

			cam1@vcam1 {
				phandle = <0x4b>;

				pins_cmd_dat {
					output-high;
					pinmux = <0xa900>;
					slew-rate = <0x1>;
				};
			};

			cam1@vcam2 {
				phandle = <0x4c>;

				pins_cmd_dat {
					output-low;
					pinmux = <0xa900>;
					slew-rate = <0x1>;
				};
			};

			cam1@vcam3 {
				phandle = <0x4d>;

				pins_cmd_dat {
					output-high;
					pinmux = <0xa900>;
					slew-rate = <0x1>;
				};
			};

			cam2@0 {
				phandle = <0x44>;

				pins_cmd_dat {
					output-low;
					pinmux = <0x6d00>;
					slew-rate = <0x1>;
				};
			};

			cam2@1 {
				phandle = <0x45>;

				pins_cmd_dat {
					output-high;
					pinmux = <0x6d00>;
					slew-rate = <0x1>;
				};
			};

			cam2@3 {
				phandle = <0x46>;

				pins_cmd_dat {
					output-low;
					pinmux = <0x6b00>;
					slew-rate = <0x1>;
				};
			};

			cam2@4 {
				phandle = <0x47>;

				pins_cmd_dat {
					output-high;
					pinmux = <0x6b00>;
					slew-rate = <0x1>;
				};
			};

			cam2@vcam0 {
				phandle = <0x4a>;

				pins_cmd_dat {
					output-low;
					pinmux = <0xa900>;
					slew-rate = <0x1>;
				};
			};

			camdefault {
				phandle = <0x3b>;
			};

			camera_pins_cam0_mclk_2ma {
				phandle = <0x4f>;

				pins_cmd_dat {
					drive-strength = <0x0>;
					pinmux = <0x6301>;
				};
			};

			camera_pins_cam0_mclk_4ma {
				phandle = <0x50>;

				pins_cmd_dat {
					drive-strength = <0x1>;
					pinmux = <0x6301>;
				};
			};

			camera_pins_cam0_mclk_6ma {
				phandle = <0x51>;

				pins_cmd_dat {
					drive-strength = <0x2>;
					pinmux = <0x6301>;
				};
			};

			camera_pins_cam0_mclk_8ma {
				phandle = <0x52>;

				pins_cmd_dat {
					drive-strength = <0x3>;
					pinmux = <0x6301>;
				};
			};

			camera_pins_cam0_mclk_off {
				phandle = <0x4e>;

				pins_cmd_dat {
					drive-strength = <0x1>;
					pinmux = <0x6300>;
				};
			};

			camera_pins_cam1_mclk_2ma {
				phandle = <0x54>;

				pins_cmd_dat {
					drive-strength = <0x0>;
					pinmux = <0x6401>;
				};
			};

			camera_pins_cam1_mclk_4ma {
				phandle = <0x55>;

				pins_cmd_dat {
					drive-strength = <0x1>;
					pinmux = <0x6401>;
				};
			};

			camera_pins_cam1_mclk_6ma {
				phandle = <0x56>;

				pins_cmd_dat {
					drive-strength = <0x2>;
					pinmux = <0x6401>;
				};
			};

			camera_pins_cam1_mclk_8ma {
				phandle = <0x57>;

				pins_cmd_dat {
					drive-strength = <0x3>;
					pinmux = <0x6401>;
				};
			};

			camera_pins_cam1_mclk_off {
				phandle = <0x53>;

				pins_cmd_dat {
					drive-strength = <0x1>;
					pinmux = <0x6400>;
				};
			};

			camera_pins_cam2_mclk_2ma {
				phandle = <0x59>;

				pins_cmd_dat {
					drive-strength = <0x0>;
					pinmux = <0x6c01>;
				};
			};

			camera_pins_cam2_mclk_4ma {
				phandle = <0x5a>;

				pins_cmd_dat {
					drive-strength = <0x1>;
					pinmux = <0x6c01>;
				};
			};

			camera_pins_cam2_mclk_6ma {
				phandle = <0x5b>;

				pins_cmd_dat {
					drive-strength = <0x2>;
					pinmux = <0x6c01>;
				};
			};

			camera_pins_cam2_mclk_8ma {
				phandle = <0x5c>;

				pins_cmd_dat {
					drive-strength = <0x3>;
					pinmux = <0x6c01>;
				};
			};

			camera_pins_cam2_mclk_off {
				phandle = <0x58>;

				pins_cmd_dat {
					drive-strength = <0x1>;
					pinmux = <0x6c00>;
				};
			};
		};
	};

	fragment@23 {
		target = <0xffffffff>;

		__overlay__ {
			cam0_enable_sensor = "imx519_mipi_raw s5k3p8sx_mipi_raw ov13855_mipi_raw s5k3p9sx_mipi_raw";
			cam0_vcama-supply = <0xffffffff>;
			cam0_vcamd-supply = <0xffffffff>;
			cam0_vcamio-supply = <0xffffffff>;
			cam1_enable_sensor = "imx576_mipi_raw imx476_mipi_raw s5k4h7_mipi_raw hi846p2q_mipi_raw imx371_mipi_raw imx376_mipi_raw";
			cam1_vcama-supply = <0xffffffff>;
			cam1_vcamd-supply = <0xffffffff>;
			cam1_vcamio-supply = <0xffffffff>;
			pinctrl-0 = <0x3b>;
			pinctrl-1 = <0x3c>;
			pinctrl-10 = <0x45>;
			pinctrl-11 = <0x46>;
			pinctrl-12 = <0x47>;
			pinctrl-13 = <0x48>;
			pinctrl-14 = <0x49>;
			pinctrl-15 = <0x4a>;
			pinctrl-16 = <0x4b>;
			pinctrl-17 = <0x4c>;
			pinctrl-18 = <0x4d>;
			pinctrl-19 = <0x4e>;
			pinctrl-2 = <0x3d>;
			pinctrl-20 = <0x4f>;
			pinctrl-21 = <0x50>;
			pinctrl-22 = <0x51>;
			pinctrl-23 = <0x52>;
			pinctrl-24 = <0x53>;
			pinctrl-25 = <0x54>;
			pinctrl-26 = <0x55>;
			pinctrl-27 = <0x56>;
			pinctrl-28 = <0x57>;
			pinctrl-29 = <0x58>;
			pinctrl-3 = <0x3e>;
			pinctrl-30 = <0x59>;
			pinctrl-31 = <0x5a>;
			pinctrl-32 = <0x5b>;
			pinctrl-33 = <0x5c>;
			pinctrl-4 = <0x3f>;
			pinctrl-5 = <0x40>;
			pinctrl-6 = <0x41>;
			pinctrl-7 = <0x42>;
			pinctrl-8 = <0x43>;
			pinctrl-9 = <0x44>;
			pinctrl-names = "default", "cam0_rst0", "cam0_rst1", "cam0_pnd0", "cam0_pnd1", "cam1_rst0", "cam1_rst1", "cam1_pnd0", "cam1_pnd1", "cam2_rst0", "cam2_rst1", "cam2_pnd0", "cam2_pnd1", "cam0_ldo_vcamd_0", "cam0_ldo_vcamd_1", "cam2_ldo_vcamd_0", "cam2_ldo_vcamd_1", "cam2_ldo_vcama_0", "cam2_ldo_vcama_1", "cam0_mclk_off", "cam0_mclk_2mA", "cam0_mclk_4mA", "cam0_mclk_6mA", "cam0_mclk_8mA", "cam1_mclk_off", "cam1_mclk_2mA", "cam1_mclk_4mA", "cam1_mclk_6mA", "cam1_mclk_8mA", "cam2_mclk_off", "cam2_mclk_2mA", "cam2_mclk_4mA", "cam2_mclk_6mA", "cam2_mclk_8mA";
			status = "okay";
		};
	};

	fragment@24 {
		target = <0xffffffff>;

		__overlay__ {
			pinctrl-0 = <0x5d>;
			pinctrl-1 = <0x5e>;
			pinctrl-2 = <0x5f>;
			pinctrl-3 = <0x60>;
			pinctrl-4 = <0x61>;
			pinctrl-5 = <0x62>;
			pinctrl-6 = <0x63>;
			pinctrl-names = "uart0_gpio_default", "uart0_rx_set", "uart0_rx_clear", "uart0_tx_set", "uart0_tx_clear", "uart0_rx_gpio", "uart0_tx_gpio";
			status = "okay";
		};
	};

	fragment@25 {
		target = <0xffffffff>;

		__overlay__ {

			uart0_rx_clear@gpio95 {
				phandle = <0x5f>;

				pins_cmd_dat {
					output-high;
					pinmux = <0x5f00>;
					slew-rate = <0x1>;
				};
			};

			uart0_rx_gpio@gpio95 {
				phandle = <0x62>;

				pins_cmd_dat {
					bias-disable;
					input-enable;
					pinmux = <0x5f00>;
					slew-rate = <0x0>;
				};
			};

			uart0_rx_set@gpio95 {
				phandle = <0x5e>;

				pins_cmd_dat {
					pinmux = <0x5f01>;
				};
			};

			uart0_tx_clear@gpio96 {
				phandle = <0x61>;

				pins_cmd_dat {
					output-high;
					pinmux = <0x6000>;
					slew-rate = <0x1>;
				};
			};

			uart0_tx_gpio@gpio96 {
				phandle = <0x63>;

				pins_cmd_dat {
					bias-disable;
					input-enable;
					pinmux = <0x6000>;
					slew-rate = <0x0>;
				};
			};

			uart0_tx_set@gpio96 {
				phandle = <0x60>;

				pins_cmd_dat {
					pinmux = <0x6001>;
				};
			};

			uart0gpiodefault {
				phandle = <0x5d>;
			};
		};
	};

	fragment@26 {
		target = <0xffffffff>;

		__overlay__ {
			pinctrl-0 = <0x64>;
			pinctrl-1 = <0x65>;
			pinctrl-names = "irtx_gpio_led_default", "irtx_gpio_led_set";
			status = "okay";
		};
	};

	fragment@27 {
		target = <0xffffffff>;

		__overlay__ {

			irtx_gpio_led_def@gpio90 {
				phandle = <0x64>;

				pins_cmd_dat {
					bias-disable;
					input-schmitt-enable = <0x0>;
					output-low;
					pinmux = <0x5a00>;
					slew-rate = <0x1>;
				};
			};

			irtx_gpio_led_set@gpio90 {
				phandle = <0x65>;

				pins_cmd_dat {
					output-high;
					pinmux = <0x5a01>;
					slew-rate = <0x1>;
				};
			};
		};
	};

	fragment@28 {
		target = <0xffffffff>;

		__overlay__ {
			mt6370,intr_gpio = <0xffffffff 0xa 0x0>;
			mt6370,intr_gpio_num = <0xa>;
		};
	};

	fragment@29 {
		target = <0xffffffff>;

		__overlay__ {
			mt6370pd,intr_gpio = <0xffffffff 0x29 0x0>;
			mt6370pd,intr_gpio_num = <0x29>;
		};
	};

	fragment@3 {
		target = <0xffffffff>;

		__overlay__ {
			core_1 = "enable";
			scp_sramSize = <0x80000>;
		};
	};

	fragment@30 {
		target = <0xffffffff>;

		__overlay__ {
			keypad,volume-down = <0xffffffff 0x5e 0x0>;
			keypad,volume-up = <0xffffffff 0x14 0x0>;
			pinctrl-0 = <0x66>;
			pinctrl-1 = <0x67>;
			pinctrl-names = "volume_up_as_int", "volume_down_as_int";
			status = "okay";
		};
	};

	fragment@31 {
		target = <0xffffffff>;

		__overlay__ {

			volume_down@0 {
				phandle = <0x67>;

				pins_cmd_dat {
					bias-pull-up = <0x0>;
					input-enable;
					pinmux = <0x5e00>;
					slew-rate = <0x0>;
				};
			};

			volume_up@0 {
				phandle = <0x66>;

				pins_cmd_dat {
					bias-pull-up = <0x0>;
					input-enable;
					pinmux = <0x1400>;
					slew-rate = <0x0>;
				};
			};
		};
	};

	fragment@32 {
		target = <0xffffffff>;

		__overlay__ {
			pinctrl-0 = <0x68>;
			pinctrl-1 = <0x69>;
			pinctrl-names = "msdc1_on", "msdc1_off";
			status = "okay";
		};
	};

	fragment@33 {
		target = <0xffffffff>;

		__overlay__ {

			sd0@0 {
				phandle = <0x68>;

				pins_cmd_dat {
					output-high;
					pinmux = <0x5a00>;
					slew-rate = <0x1>;
				};
			};

			sd0@1 {
				phandle = <0x69>;

				pins_cmd_dat {
					output-low;
					pinmux = <0x5a00>;
					slew-rate = <0x1>;
				};
			};
		};
	};

	fragment@34 {
		target = <0xffffffff>;

		__overlay__ {
			#address-cells = <0x1>;
			#size-cells = <0x0>;

			himax_hx83112b@48 {
				black_gesture_support;
				black_gesture_test_support;
				charger_pump_support;
				chip-name = "HIMAX83112B";
				compatible = "himax83112b";
				edge_limit_support;
				fw_update_app_support;
				incell_screen;
				interrupt-parent = <0xffffffff>;
				interrupts = <0x1 0x2008 0x1 0x0>;
				irq-gpio = <0xffffffff 0x1 0x2002>;
				pinctrl-names = "default";
				reg = <0x48>;
				reset-gpio = <0xffffffff 0x2a 0x0>;
				status = "okay";
				touchpanel,button-type = <0x2 0x5>;
				touchpanel,default_hor_area = <0x7>;
				touchpanel,display-coords = <0x438 0x8e8>;
				touchpanel,max-num-support = <0xa>;
				touchpanel,panel-coords = <0x438 0x8e8>;
				touchpanel,tx-rx-num = <0x10 0x24>;
			};

			nova_nt36672@62 {
				black_gesture_support;
				black_gesture_test_support;
				charger_pump_support;
				chip-name = "NT36672A";
				compatible = "nova-nt36672";
				edge_limit_support;
				fw_update_app_support;
				incell_screen;
				interrupt-parent = <0xffffffff>;
				interrupts = <0x1 0x2001 0x1 0x0>;
				irq-gpio = <0xffffffff 0x1 0x2001>;
				reg = <0x62>;
				reset-gpio = <0xffffffff 0x2a 0x0>;
				status = "okay";
				touchpanel,button-type = <0x2 0x5>;
				touchpanel,default_hor_area = <0x7>;
				touchpanel,display-coords = <0x438 0x8e8>;
				touchpanel,max-num-support = <0xa>;
				touchpanel,panel-coords = <0x438 0x8e8>;
				touchpanel,tx-rx-num = <0x10 0x24>;
			};

			synatpics_td4310@21 {
				black_gesture_support;
				black_gesture_test_support;
				chip-name = "TD4310";
				compatible = "synaptics-td4310";
				edge_limit_support;
				fw_update_app_support;
				incell_screen;
				interrupt-parent = <0xffffffff>;
				interrupts = <0x1 0x2008 0x1 0x0>;
				irq-gpio = <0xffffffff 0x1 0x2008>;
				pinctrl-names = "default";
				reg = <0x21>;
				status = "okay";
				touchpanel,button-type = <0x2 0x5>;
				touchpanel,default_hor_area = <0x7>;
				touchpanel,display-coords = <0x438 0x870>;
				touchpanel,max-num-support = <0xa>;
				touchpanel,panel-coords = <0x438 0x870>;
				touchpanel,tx-rx-num = <0x12 0x20>;
			};

			synatpics_td4330@20 {
				black_gesture_support;
				black_gesture_test_support;
				charger_pump_support;
				chip-name = "TD4330";
				compatible = "synaptics-td4330";
				edge_limit_support;
				fw_update_app_support;
				incell_screen;
				interrupt-parent = <0xffffffff>;
				interrupts = <0x1 0x2008 0x1 0x0>;
				irq-gpio = <0xffffffff 0x1 0x2008>;
				pinctrl-names = "default";
				reg = <0x20>;
				reset-gpio = <0xffffffff 0x2a 0x0>;
				status = "okay";
				touchpanel,button-type = <0x2 0x5>;
				touchpanel,default_hor_area = <0x7>;
				touchpanel,display-coords = <0x438 0x8e8>;
				touchpanel,int-mode = <0x1>;
				touchpanel,max-num-support = <0xa>;
				touchpanel,panel-coords = <0x438 0x8e8>;
				touchpanel,tx-rx-num = <0x10 0x24>;
			};
		};
	};

	fragment@35 {
		target = <0xffffffff>;

		__overlay__ {

			fpc_irq_default {
				phandle = <0x6b>;

				pins_cmd_dat {
					bias-pull-up = <0x0>;
					pinmux = <0xa00>;
					slew-rate = <0x0>;
				};
			};

			fpc_pwr_default {
				phandle = <0x6c>;

				pins_cmd_dat {
					output-low;
					pinmux = <0x5000>;
					slew-rate = <0x1>;
				};
			};

			fpc_reset_default {
				phandle = <0x6a>;

				pins_cmd_dat {
					output-low;
					pinmux = <0x4f00>;
					slew-rate = <0x1>;
				};
			};

			gpio_fpc_cs_func {
				phandle = <0x6d>;

				pins_cmd_dat {
					drive-strength = <0x3>;
					pinmux = <0x5601>;
				};
			};
		};
	};

	fragment@36 {
		target = <0xffffffff>;

		__overlay__ {
			fpc,gpio_cs = <0xffffffff 0x56 0x0>;
			fpc,irq-gpio = <0xffffffff 0xa 0x0>;
			fpc,reset-gpio = <0xffffffff 0x4f 0x0>;
			fpc,vdd-en = <0xffffffff 0x5a 0x0>;
			pinctrl-0 = <0x6a 0x6b 0x6c>;
			pinctrl-1 = <0x6d>;
			pinctrl-names = "default", "fpc_cs_func";
			status = "okay";
			vdd_io-supply = <0xffffffff>;
			vddio-config = <0x1b7740 0x1b7740 0x1770>;

			power_source_1 {
				delay-time = <0x0>;
				power-config = "vddio-config";
				power-mode = <0x1>;
				power-name = "vdd_io";
			};

			power_source_2 {
				delay-time = <0x0>;
				power-mode = <0x2>;
				power-name = "fpc,vdd-en";
				poweron-level = <0x1>;
			};
		};
	};

	fragment@37 {
		target = <0xffffffff>;

		__overlay__ {

			goodix_irq_no_pull {
				phandle = <0x71>;

				pins_cmd_dat {
					bias-disable;
					pinmux = <0xa00>;
					slew-rate = <0x0>;
				};
			};

			goodix_irq_out_low {
				phandle = <0x70>;

				pins_cmd_dat {
					output-low;
					pinmux = <0xa00>;
					slew-rate = <0x1>;
				};
			};

			goodix_ldo_default {
				phandle = <0x6f>;

				pins_cmd_dat {
					output-low;
					pinmux = <0x5a00>;
					slew-rate = <0x1>;
				};
			};

			goodix_reset_default {
				phandle = <0x6e>;

				pins_cmd_dat {
					output-low;
					pinmux = <0x4f00>;
					slew-rate = <0x1>;
				};
			};

			gpio_goodix_cs_func {
				phandle = <0x72>;

				pins_cmd_dat {
					drive-strength = <0x3>;
					pinmux = <0x5601>;
				};
			};
		};
	};

	fragment@38 {
		target = <0xffffffff>;

		__overlay__ {
			goodix,gpio_cs = <0xffffffff 0x56 0x0>;
			goodix,gpio_irq = <0xffffffff 0xa 0x0>;
			goodix,gpio_ldo = <0xffffffff 0x5a 0x0>;
			goodix,gpio_reset = <0xffffffff 0x4f 0x0>;
			interrupt-parent = <0xffffffff>;
			interrupts = <0xa 0x0>;
			pinctrl-0 = <0x6e>;
			pinctrl-1 = <0x6f>;
			pinctrl-2 = <0x70>;
			pinctrl-3 = <0x71>;
			pinctrl-4 = <0x72>;
			pinctrl-names = "goodix_reset_default", "goodix_ldo_default", "goodix_irq_out_low", "goodix_irq_no_pull", "gf_cs_func";
			spi-max-frequency = <0x7a1200>;
			status = "okay";
		};
	};

	fragment@39 {
		target = <0xffffffff>;

		__overlay__ {
			#address-cells = <0x1>;
			#size-cells = <0x0>;
			status = "okay";

			fingerprint@0 {
				compatible = "oppo,oppo_fp";
				ldo_gpio = <0xffffffff 0x5a 0x0>;
				phandle = <0x83>;
				reg = <0x0>;
				spi-id = <0x0>;
				spi-irq = <0x27>;
				spi-max-frequency = <0x7a1200>;
				spi-reg = <0xa7ffd0>;
				status = "okay";

				power_source_1 {
					delay-time = <0x0>;
					power-mode = <0x2>;
					power-name = "ldo_gpio";
					poweron-level = <0x1>;
				};
			};
		};
	};

	fragment@4 {
		target = <0xffffffff>;

		__overlay__ {
			#address-cells = <0x1>;
			#size-cells = <0x0>;

			i2c_bl_lm3697@36 {
				compatible = "mediatek,i2c_bl_lm3697";
				reg = <0x36>;
				status = "okay";
			};

			i2c_lcd_bias@3e {
				compatible = "mediatek,i2c_lcd_bias";
				reg = <0x3e>;
				status = "okay";
			};
		};
	};

	fragment@40 {
		target = <0xffffffff>;

		__overlay__ {
			oppo,fp_gpio = <0x1f1>;
			pinctrl-names = "default";

			fpc_1023 {
				chip-name = "F_1023";
				eng-menu = "-1,-1";
				oppo,fp-id = <0x0>;
				vendor-chip = <0x1>;
			};

			goodix_5298 {
				chip-name = "G_5298";
				eng-menu = "-1,-1";
				oppo,fp-id = <0x1>;
				vendor-chip = <0x9>;
			};
		};
	};

	fragment@41 {
		target = <0xffffffff>;

		__overlay__ {

			active@id1 {
				phandle = <0x4>;

				pins_cmd_dat {
					bias-pull-up = <0x0>;
					input-enable;
					pinmux = <0xb000>;
					slew-rate = <0x0>;
				};
			};

			active@id2 {
				phandle = <0x5>;

				pins_cmd_dat {
					bias-pull-up = <0x0>;
					input-enable;
					pinmux = <0x3a00>;
					slew-rate = <0x0>;
				};
			};

			active@id5 {
				phandle = <0x6>;

				pins_cmd_dat {
					bias-pull-down;
					input-enable;
					pinmux = <0x5c00>;
					slew-rate = <0x0>;
				};
			};

			active@id6 {
				phandle = <0x7>;

				pins_cmd_dat {
					bias-pull-down;
					input-enable;
					pinmux = <0xf00>;
					slew-rate = <0x0>;
				};
			};

			default@hw_sub_id {
				phandle = <0x1>;
			};

			sleep@id1 {
				phandle = <0x2>;

				pins_cmd_dat {
					bias-pull-down = <0x0>;
					input-enable;
					pinmux = <0xb000>;
					slew-rate = <0x0>;
				};
			};

			sleep@id2 {
				phandle = <0x3>;

				pins_cmd_dat {
					bias-pull-down = <0x0>;
					input-enable;
					pinmux = <0x3a00>;
				};
			};
		};
	};

	fragment@42 {
		target = <0xffffffff>;

		__overlay__ {

			adc_channel@ {
				compatible = "mediatek,adc_channel";
				mediatek,adc_fdd_rf_params_dynamic_custom_ch = <0x2>;
				mediatek,temperature0 = <0x0>;
				mediatek,temperature1 = <0x1>;
				status = "okay";
			};
		};
	};

	fragment@43 {
		target = <0xffffffff>;

		__overlay__ {
			mediatek,clkbuf-config = <0x2 0x1 0x1 0x2 0x0 0x0 0x1>;
			mediatek,clkbuf-driving-current = <0xffffffff 0xffffffff 0xffffffff 0xffffffff 0xffffffff 0xffffffff 0xffffffff>;
			mediatek,clkbuf-quantity = <0x7>;
			status = "okay";
		};
	};

	fragment@44 {
		target = <0xffffffff>;

		__overlay__ {
			#address-cells = <0x1>;
			#size-cells = <0x0>;
			clock-frequency = <0x61a80>;
			mediatek,use-open-drain;

			cap_touch@5d {
				compatible = "mediatek,cap_touch";
				phandle = <0x84>;
				reg = <0x5d>;
				status = "okay";
			};
		};
	};

	fragment@45 {
		target = <0xffffffff>;

		__overlay__ {
			#address-cells = <0x1>;
			#size-cells = <0x0>;
			clock-frequency = <0x61a80>;
			mediatek,use-open-drain;

			alsps@51 {
				compatible = "mediatek,alsps";
				interrupt-parent = <0xffffffff>;
				interrupts = <0x6 0x8 0x6 0x0>;
				phandle = <0x86>;
				reg = <0x51>;
				status = "okay";
			};

			barometer@77 {
				compatible = "mediatek,barometer";
				phandle = <0x87>;
				reg = <0x77>;
				status = "okay";
			};

			msensor@0c {
				compatible = "mediatek,msensor";
				phandle = <0x85>;
				reg = <0xc>;
				status = "okay";
			};
		};
	};

	fragment@46 {
		target = <0xffffffff>;

		__overlay__ {
			#address-cells = <0x1>;
			#size-cells = <0x0>;
			clock-frequency = <0x61a80>;
			mediatek,use-open-drain;
		};
	};

	fragment@47 {
		target = <0xffffffff>;

		__overlay__ {
			#address-cells = <0x1>;
			#size-cells = <0x0>;
			clock-frequency = <0x61a80>;
			mediatek,use-open-drain;

			nfc@08 {
				compatible = "mediatek,nfc";
				phandle = <0x88>;
				reg = <0x8>;
				status = "okay";
			};
		};
	};

	fragment@48 {
		target = <0xffffffff>;

		__overlay__ {
			#address-cells = <0x1>;
			#size-cells = <0x0>;
			clock-frequency = <0x61a80>;
			mediatek,use-open-drain;

			camera_main@1a {
				compatible = "mediatek,camera_main";
				phandle = <0x89>;
				reg = <0x1a>;
				status = "okay";
			};

			camera_main_af@72 {
				compatible = "mediatek,camera_main_af";
				phandle = <0x8a>;
				reg = <0x72>;
				status = "okay";
			};

			camera_main_eeprom@50 {
				compatible = "mediatek,camera_main_eeprom";
				phandle = <0x8b>;
				reg = <0x50>;
				status = "okay";
			};

			camera_main_two@10 {
				compatible = "mediatek,camera_main_two";
				phandle = <0x8c>;
				reg = <0x10>;
				status = "okay";
			};

			camera_main_two_af@72 {
				compatible = "mediatek,camera_main_two_af";
				phandle = <0x8d>;
				reg = <0x72>;
				status = "okay";
			};

			camera_main_two_eeprom@51 {
				compatible = "mediatek,camera_main_two_eeprom";
				phandle = <0x8e>;
				reg = <0x51>;
				status = "okay";
			};

			camera_sub@35 {
				compatible = "mediatek,camera_sub";
				phandle = <0x8f>;
				reg = <0x35>;
				status = "okay";
			};

			camera_sub_eeprom@54 {
				compatible = "mediatek,camera_sub_eeprom";
				phandle = <0x90>;
				reg = <0x54>;
				status = "okay";
			};

			ccu_sensor_i2c_4_hw@33 {
				compatible = "mediatek,ccu_sensor_i2c_4_hw";
				phandle = <0x92>;
				reg = <0x33>;
				status = "okay";
			};

			strobe_main@63 {
				compatible = "mediatek,strobe_main";
				phandle = <0x91>;
				reg = <0x63>;
				status = "okay";
			};
		};
	};

	fragment@49 {
		target = <0xffffffff>;

		__overlay__ {
			#address-cells = <0x1>;
			#size-cells = <0x0>;
			clock-frequency = <0x61a80>;
			mediatek,use-open-drain;

			subpmic_pmu@34 {
				compatible = "mediatek,subpmic_pmu";
				phandle = <0x94>;
				reg = <0x34>;
				status = "okay";
			};

			usb_type_c@4e {
				compatible = "mediatek,usb_type_c";
				phandle = <0x93>;
				reg = <0x4e>;
				status = "okay";
			};
		};
	};

	fragment@5 {
		target = <0xffffffff>;

		__overlay__ {

			default {
				phandle = <0xe>;
			};

			lcd_1p8_en0_gpio {
				phandle = <0x19>;

				pins_cmd_dat {
					output-low;
					pinmux = <0x4100>;
					slew-rate = <0x1>;
				};
			};

			lcd_1p8_en1_gpio {
				phandle = <0x1a>;

				pins_cmd_dat {
					output-high;
					pinmux = <0x4100>;
					slew-rate = <0x1>;
				};
			};

			lcd_bias_enn0_gpio {
				phandle = <0x15>;

				pins_cmd_dat {
					output-low;
					pinmux = <0x1800>;
					slew-rate = <0x1>;
				};
			};

			lcd_bias_enn1_gpio {
				phandle = <0x16>;

				pins_cmd_dat {
					output-high;
					pinmux = <0x1800>;
					slew-rate = <0x1>;
				};
			};

			lcd_bias_enp0_gpio {
				phandle = <0x13>;

				pins_cmd_dat {
					output-low;
					pinmux = <0x1700>;
					slew-rate = <0x1>;
				};
			};

			lcd_bias_enp1_gpio {
				phandle = <0x14>;

				pins_cmd_dat {
					output-high;
					pinmux = <0x1700>;
					slew-rate = <0x1>;
				};
			};

			lcd_bl_en0_gpio {
				phandle = <0x17>;

				pins_cmd_dat {
					output-low;
					pinmux = <0x4200>;
					slew-rate = <0x1>;
				};
			};

			lcd_bl_en1_gpio {
				phandle = <0x18>;

				pins_cmd_dat {
					output-high;
					pinmux = <0x4200>;
					slew-rate = <0x1>;
				};
			};

			lcm_rst_out0_gpio {
				phandle = <0x11>;

				pins_cmd_dat {
					output-low;
					pinmux = <0x2d00>;
					slew-rate = <0x1>;
				};
			};

			lcm_rst_out1_gpio {
				phandle = <0x12>;

				pins_cmd_dat {
					output-high;
					pinmux = <0x2d00>;
					slew-rate = <0x1>;
				};
			};

			mode_te_gpio {
				phandle = <0xf>;

				pins_cmd_dat {
					pinmux = <0x2c00>;
				};
			};

			mode_te_te {
				phandle = <0x10>;

				pins_cmd_dat {
					pinmux = <0x2c01>;
				};
			};
		};
	};

	fragment@50 {
		target = <0xffffffff>;

		__overlay__ {
			#address-cells = <0x1>;
			#size-cells = <0x0>;
			clock-frequency = <0x61a80>;
			mediatek,use-open-drain;

			slave_charger@4b {
				compatible = "mediatek,slave_charger";
				phandle = <0x96>;
				reg = <0x4b>;
				status = "okay";
			};

			speaker_amp@34 {
				compatible = "mediatek,speaker_amp";
				phandle = <0x95>;
				reg = <0x34>;
				status = "okay";
			};
		};
	};

	fragment@51 {
		target = <0xffffffff>;

		__overlay__ {
			#address-cells = <0x1>;
			#size-cells = <0x0>;
			clock-frequency = <0x61a80>;
			mediatek,use-open-drain;
		};
	};

	fragment@52 {
		target = <0xffffffff>;

		__overlay__ {
			#address-cells = <0x1>;
			#size-cells = <0x0>;
			clock-frequency = <0x61a80>;
			mediatek,use-open-drain;
		};
	};

	fragment@53 {
		target = <0xffffffff>;

		__overlay__ {
			#address-cells = <0x1>;
			#size-cells = <0x0>;
			clock-frequency = <0x61a80>;
			mediatek,use-open-drain;
		};
	};

	fragment@54 {
		target = <0xffffffff>;

		__overlay__ {
			#address-cells = <0x1>;
			#size-cells = <0x0>;
			clock-frequency = <0x61a80>;
			mediatek,use-open-drain;
		};
	};

	fragment@55 {
		target = <0xffffffff>;

		__overlay__ {
			#address-cells = <0x1>;
			#size-cells = <0x0>;
			clock-frequency = <0x61a80>;
			mediatek,use-open-drain;
		};
	};

	fragment@56 {
		target = <0xffffffff>;

		__overlay__ {
			GPIO_SIM1_HOT_PLUG = <0xffffffff 0x2f 0x0>;
			GPIO_SIM1_SCLK = <0xffffffff 0x26 0x0>;
			GPIO_SIM1_SIO = <0xffffffff 0x28 0x0>;
			GPIO_SIM1_SRST = <0xffffffff 0x27 0x0>;
			GPIO_SIM2_HOT_PLUG = <0xffffffff 0x2e 0x0>;
			GPIO_SIM2_SCLK = <0xffffffff 0x25 0x0>;
			GPIO_SIM2_SIO = <0xffffffff 0x23 0x0>;
			GPIO_SIM2_SRST = <0xffffffff 0x24 0x0>;
		};
	};

	fragment@57 {
		target = <0xffffffff>;

		__overlay__ {
			gpio_init_default = <0x0 0x0 0x0 0x0 0x1 0x1 0x1 0x1 0x0 0x0 0x0 0x0 0x0 0x1 0x2 0x0 0x0 0x0 0x1 0x1 0x1 0x3 0x0 0x0 0x0 0x1 0x1 0x1 0x4 0x0 0x0 0x0 0x1 0x0 0x0 0x5 0x0 0x0 0x0 0x1 0x1 0x0 0x6 0x0 0x0 0x0 0x1 0x1 0x0 0x7 0x0 0x0 0x0 0x1 0x1 0x0 0x8 0x7 0x0 0x0 0x1 0x1 0x0 0x9 0x0 0x1 0x0 0x0 0x0 0x0 0xa 0x0 0x0 0x0 0x1 0x0 0x0 0xb 0x3 0x0 0x0 0x0 0x0 0x0 0xc 0x3 0x0 0x0 0x0 0x0 0x0 0xd 0x2 0x0 0x0 0x1 0x0 0x0 0xe 0x0 0x0 0x0 0x0 0x0 0x0 0xf 0x0 0x0 0x0 0x0 0x0 0x0 0x10 0x0 0x1 0x0 0x1 0x0 0x0 0x11 0x0 0x0 0x0 0x1 0x0 0x0 0x12 0x0 0x1 0x1 0x1 0x0 0x0 0x13 0x0 0x1 0x1 0x0 0x0 0x0 0x14 0x0 0x0 0x0 0x1 0x0 0x0 0x15 0x2 0x0 0x0 0x1 0x0 0x0 0x16 0x4 0x0 0x0 0x1 0x0 0x0 0x17 0x0 0x1 0x0 0x0 0x0 0x0 0x18 0x0 0x1 0x0 0x0 0x0 0x0 0x19 0x0 0x0 0x0 0x0 0x0 0x0 0x1a 0x0 0x0 0x0 0x0 0x0 0x0 0x1b 0x5 0x1 0x0 0x0 0x0 0x0 0x1c 0x5 0x0 0x0 0x1 0x1 0x0 0x1d 0x1 0x1 0x0 0x0 0x0 0x0 0x1e 0x1 0x0 0x0 0x1 0x1 0x0 0x1f 0x1 0x0 0x0 0x1 0x1 0x0 0x20 0x1 0x0 0x0 0x1 0x1 0x0 0x21 0x1 0x0 0x0 0x1 0x1 0x0 0x22 0x1 0x0 0x0 0x1 0x1 0x0 0x23 0x1 0x0 0x0 0x1 0x1 0x0 0x24 0x1 0x1 0x0 0x0 0x0 0x0 0x25 0x1 0x1 0x0 0x0 0x0 0x0 0x26 0x1 0x1 0x0 0x0 0x0 0x0 0x27 0x1 0x1 0x0 0x0 0x0 0x0 0x28 0x1 0x0 0x0 0x1 0x1 0x0 0x29 0x0 0x0 0x0 0x1 0x1 0x0 0x2a 0x0 0x1 0x0 0x0 0x0 0x0 0x2b 0x1 0x1 0x0 0x0 0x0 0x0 0x2c 0x1 0x0 0x0 0x1 0x0 0x0 0x2d 0x0 0x1 0x0 0x0 0x0 0x0 0x2e 0x1 0x0 0x0 0x1 0x1 0x0 0x2f 0x1 0x0 0x0 0x1 0x1 0x0 0x30 0x1 0x0 0x0 0x0 0x0 0x0 0x31 0x1 0x0 0x0 0x0 0x0 0x0 0x32 0x1 0x0 0x0 0x1 0x1 0x0 0x33 0x1 0x0 0x0 0x1 0x1 0x0 0x34 0x1 0x1 0x0 0x1 0x0 0x0 0x35 0x1 0x1 0x0 0x1 0x0 0x0 0x36 0x1 0x1 0x0 0x1 0x0 0x0 0x37 0x1 0x1 0x0 0x1 0x0 0x0 0x38 0x1 0x1 0x0 0x1 0x0 0x0 0x39 0x1 0x1 0x0 0x1 0x0 0x0 0x3a 0x0 0x0 0x0 0x1 0x1 0x0 0x3b 0x1 0x0 0x0 0x1 0x0 0x0 0x3c 0x1 0x0 0x0 0x1 0x0 0x0 0x3d 0x1 0x0 0x0 0x1 0x0 0x0 0x3e 0x1 0x0 0x0 0x1 0x0 0x0 0x3f 0x1 0x0 0x0 0x1 0x0 0x0 0x40 0x1 0x0 0x0 0x1 0x0 0x0 0x41 0x0 0x1 0x0 0x0 0x0 0x0 0x42 0x2 0x0 0x0 0x1 0x0 0x0 0x43 0x1 0x0 0x0 0x1 0x0 0x0 0x44 0x1 0x0 0x0 0x1 0x0 0x0 0x45 0x1 0x1 0x0 0x1 0x0 0x0 0x46 0x1 0x1 0x0 0x1 0x0 0x0 0x47 0x1 0x1 0x0 0x1 0x0 0x0 0x48 0x1 0x1 0x0 0x1 0x0 0x0 0x49 0x1 0x1 0x0 0x1 0x0 0x0 0x4a 0x1 0x1 0x0 0x1 0x0 0x0 0x4b 0x1 0x1 0x0 0x1 0x0 0x0 0x4c 0x1 0x1 0x0 0x1 0x0 0x0 0x4d 0x1 0x1 0x0 0x1 0x0 0x0 0x4e 0x1 0x1 0x0 0x1 0x0 0x0 0x4f 0x0 0x1 0x0 0x0 0x0 0x0 0x50 0x0 0x0 0x0 0x1 0x0 0x0 0x51 0x1 0x0 0x0 0x1 0x1 0x0 0x52 0x1 0x0 0x0 0x0 0x0 0x0 0x53 0x1 0x0 0x0 0x0 0x0 0x0 0x54 0x1 0x0 0x0 0x1 0x1 0x0 0x55 0x1 0x0 0x0 0x1 0x0 0x0 0x56 0x1 0x1 0x1 0x0 0x0 0x0 0x57 0x1 0x1 0x0 0x0 0x0 0x0 0x58 0x1 0x1 0x0 0x0 0x0 0x0 0x59 0x0 0x0 0x0 0x0 0x0 0x0 0x5a 0x0 0x1 0x1 0x0 0x0 0x0 0x5b 0x0 0x0 0x0 0x1 0x1 0x0 0x5c 0x0 0x0 0x0 0x0 0x0 0x0 0x5d 0x1 0x0 0x0 0x1 0x1 0x0 0x5e 0x1 0x0 0x0 0x1 0x1 0x0 0x5f 0x1 0x0 0x0 0x1 0x1 0x0 0x60 0x1 0x1 0x0 0x0 0x0 0x0 0x61 0x0 0x1 0x0 0x0 0x0 0x0 0x62 0x0 0x1 0x0 0x0 0x0 0x0 0x63 0x0 0x1 0x0 0x0 0x0 0x0 0x64 0x0 0x1 0x0 0x0 0x0 0x0 0x65 0x0 0x1 0x0 0x0 0x0 0x0 0x66 0x0 0x1 0x0 0x0 0x0 0x0 0x67 0x1 0x0 0x0 0x1 0x1 0x0 0x68 0x1 0x0 0x0 0x1 0x1 0x0 0x69 0x1 0x0 0x0 0x0 0x0 0x0 0x6a 0x1 0x0 0x0 0x0 0x0 0x0 0x6b 0x0 0x1 0x0 0x0 0x0 0x0 0x6c 0x0 0x1 0x0 0x0 0x0 0x0 0x6d 0x0 0x1 0x0 0x0 0x0 0x0 0x6e 0x0 0x1 0x0 0x0 0x0 0x0 0x6f 0x0 0x0 0x0 0x0 0x0 0x0 0x70 0x7 0x1 0x0 0x0 0x0 0x0 0x71 0x0 0x0 0x0 0x1 0x0 0x0 0x72 0x0 0x0 0x0 0x1 0x0 0x0 0x73 0x0 0x0 0x0 0x1 0x0 0x0 0x74 0x0 0x0 0x0 0x1 0x0 0x0 0x75 0x0 0x0 0x0 0x1 0x0 0x0 0x76 0x0 0x0 0x0 0x1 0x0 0x0 0x77 0x0 0x0 0x0 0x1 0x0 0x0 0x78 0x0 0x0 0x0 0x1 0x0 0x0 0x79 0x0 0x0 0x0 0x1 0x0 0x0 0x7a 0x1 0x0 0x0 0x1 0x1 0x0 0x7b 0x1 0x0 0x0 0x1 0x1 0x0 0x7c 0x1 0x1 0x0 0x0 0x0 0x0 0x7d 0x1 0x0 0x0 0x1 0x1 0x0 0x7e 0x1 0x0 0x0 0x1 0x1 0x0 0x7f 0x1 0x0 0x0 0x1 0x1 0x0 0x80 0x1 0x0 0x0 0x1 0x1 0x0 0x81 0x1 0x0 0x0 0x1 0x1 0x0 0x82 0x1 0x0 0x0 0x1 0x1 0x0 0x83 0x1 0x0 0x0 0x1 0x0 0x0 0x84 0x1 0x0 0x0 0x1 0x1 0x0 0x85 0x1 0x1 0x1 0x0 0x0 0x0 0x86 0x1 0x0 0x0 0x1 0x0 0x1 0x87 0x1 0x1 0x0 0x0 0x0 0x0 0x88 0x1 0x1 0x0 0x1 0x0 0x0 0x89 0x1 0x1 0x0 0x1 0x0 0x0 0x8a 0x1 0x1 0x0 0x0 0x0 0x0 0x8b 0x1 0x1 0x0 0x1 0x0 0x0 0x8c 0x1 0x0 0x0 0x0 0x0 0x0 0x8d 0x1 0x0 0x0 0x0 0x0 0x0 0x8e 0x1 0x0 0x0 0x0 0x0 0x0 0x8f 0x1 0x0 0x0 0x0 0x0 0x0 0x90 0x1 0x0 0x0 0x1 0x0 0x0 0x91 0x1 0x1 0x1 0x0 0x0 0x0 0x92 0x1 0x0 0x0 0x1 0x0 0x0 0x93 0x1 0x1 0x0 0x0 0x0 0x0 0x94 0x1 0x1 0x0 0x0 0x0 0x0 0x95 0x1 0x1 0x0 0x0 0x0 0x0 0x96 0x0 0x1 0x0 0x0 0x0 0x0 0x97 0x0 0x1 0x0 0x0 0x0 0x0 0x98 0x0 0x1 0x0 0x0 0x0 0x0 0x99 0x0 0x1 0x0 0x0 0x0 0x0 0x9a 0x1 0x1 0x0 0x0 0x0 0x0 0x9b 0x1 0x0 0x0 0x1 0x0 0x0 0x9c 0x1 0x0 0x0 0x1 0x0 0x0 0x9d 0x1 0x0 0x0 0x1 0x0 0x0 0x9e 0x0 0x0 0x0 0x1 0x1 0x0 0x9f 0x0 0x1 0x0 0x0 0x0 0x0 0xa0 0x0 0x1 0x0 0x0 0x0 0x0 0xa1 0x2 0x0 0x0 0x1 0x0 0x0 0xa2 0x2 0x1 0x1 0x0 0x0 0x0 0xa3 0x2 0x1 0x0 0x0 0x0 0x0 0xa4 0x2 0x1 0x0 0x0 0x0 0x0 0xa5 0x0 0x1 0x1 0x0 0x0 0x0 0xa6 0x0 0x1 0x0 0x0 0x0 0x0 0xa7 0x1 0x1 0x0 0x1 0x0 0x0 0xa8 0x1 0x1 0x0 0x1 0x0 0x0 0xa9 0x0 0x1 0x0 0x0 0x0 0x0 0xaa 0x2 0x1 0x0 0x1 0x0 0x0 0xab 0x2 0x1 0x0 0x1 0x0 0x0 0xac 0x2 0x1 0x0 0x1 0x0 0x0 0xad 0x0 0x0 0x0 0x1 0x0 0x0 0xae 0x2 0x0 0x0 0x1 0x0 0x0 0xaf 0x0 0x1 0x0 0x0 0x0 0x0 0xb0 0x0 0x0 0x0 0x1 0x1 0x0 0xb1 0x0 0x0 0x0 0x1 0x1 0x0 0xb2 0x0 0x1 0x0 0x0 0x0 0x0 0xb3 0x0 0x1 0x0 0x0 0x0 0x0 0xb4 0x0 0x0 0x0 0x1 0x0 0x0 0xb5 0x0 0x0 0x0 0x1 0x0 0x0 0xb6 0x0 0x0 0x0 0x1 0x0 0x0 0xb7 0x0 0x0 0x0 0x1 0x0 0x0 0xb8 0x0 0x0 0x0 0x1 0x0 0x0 0xb9 0x0 0x0 0x0 0x1 0x0 0x0 0xba 0x0 0x0 0x0 0x1 0x0 0x0 0xbb 0x0 0x0 0x0 0x1 0x0 0x0 0xbc 0x0 0x0 0x0 0x1 0x0 0x0 0xbd 0x0 0x0 0x0 0x1 0x0 0x0 0xbe 0x0 0x0 0x0 0x1 0x0 0x0 0xbf 0x0 0x0 0x0 0x1 0x0 0x0>;
		};
	};

	fragment@58 {
		target = <0xffffffff>;

		__overlay__ {
			deb-gpios = <0xffffffff 0x0 0x0>;
			debounce = <0x7d000>;
			interrupt-parent = <0xffffffff>;
			interrupts = <0x0 0x8 0x0 0x0>;
			status = "okay";
		};
	};

	fragment@59 {
		target = <0xffffffff>;

		__overlay__ {
			interrupt-parent = <0xffffffff>;
			interrupts = <0x1 0x2 0x1 0x0>;
			status = "okay";
		};
	};

	fragment@6 {
		target = <0xffffffff>;

		__overlay__ {
			oppo_display_bl_set_cmdq_on_lcd_esd_recovery = <0x1>;
			oppo_display_cabc_support;
			oppo_display_elevenbits_support;
			oppo_display_ffl_support;
			oppo_display_sau_support;
			pinctrl-0 = <0xe>;
			pinctrl-1 = <0xf>;
			pinctrl-10 = <0x18>;
			pinctrl-11 = <0x19>;
			pinctrl-12 = <0x1a>;
			pinctrl-2 = <0x10>;
			pinctrl-3 = <0x11>;
			pinctrl-4 = <0x12>;
			pinctrl-5 = <0x13>;
			pinctrl-6 = <0x14>;
			pinctrl-7 = <0x15>;
			pinctrl-8 = <0x16>;
			pinctrl-9 = <0x17>;
			pinctrl-names = "default", "mode_te_gpio", "mode_te_te", "lcm_rst_out0_gpio", "lcm_rst_out1_gpio", "lcd_bias_enp0_gpio", "lcd_bias_enp1_gpio", "lcd_bias_enn0_gpio", "lcd_bias_enn1_gpio", "lcd_bl_en0_gpio", "lcd_bl_en1_gpio", "lcd_1p8_en0_gpio", "lcd_1p8_en1_gpio";
			status = "okay";
		};
	};

	fragment@60 {
		target = <0xffffffff>;

		__overlay__ {
			deb-gpios = <0xffffffff 0x3 0x0>;
			debounce = <0x3e800>;
			interrupt-parent = <0xffffffff>;
			interrupts = <0x3 0x8 0x3 0x0>;
			status = "okay";
		};
	};

	fragment@61 {
		target = <0xffffffff>;

		__overlay__ {
			interrupt-parent = <0xffffffff>;
			interrupts = <0x4 0x8 0x4 0x0>;
			status = "okay";
		};
	};

	fragment@62 {
		target = <0xffffffff>;

		__overlay__ {
			deb-gpios = <0xffffffff 0x7 0x0>;
			debounce = <0x3e800>;
			interrupt-parent = <0xffffffff>;
			interrupts = <0x7 0x8 0x7 0x0>;
			status = "okay";
		};
	};

	fragment@63 {
		target = <0xffffffff>;

		__overlay__ {
			interrupt-parent = <0xffffffff>;
			interrupts = <0xa 0x8 0xa 0x0>;
			status = "okay";
		};
	};

	fragment@64 {
		target = <0xffffffff>;

		__overlay__ {
			interrupt-parent = <0xffffffff>;
			interrupts = <0x14 0x1 0x14 0x0>;
			status = "okay";
		};
	};

	fragment@65 {
		target = <0xffffffff>;

		__overlay__ {
			interrupt-parent = <0xffffffff>;
			interrupts = <0x29 0x2 0x29 0x0>;
			status = "okay";
		};
	};

	fragment@66 {
		target = <0xffffffff>;

		__overlay__ {
			interrupt-parent = <0xffffffff>;
			interrupts = <0x2c 0x1 0x2c 0x1>;
			status = "okay";
		};
	};

	fragment@67 {
		target = <0xffffffff>;

		__overlay__ {
			interrupt-parent = <0xffffffff>;
			interrupts = <0xb6 0x4 0xbe 0x0>;
			status = "okay";
		};
	};

	fragment@68 {
		target = <0xffffffff>;

		__overlay__ {
			interrupt-parent = <0xffffffff>;
			interrupts = <0xba 0x8 0xad 0x0>;
			status = "okay";
		};
	};

	fragment@69 {
		target = <0xffffffff>;

		__overlay__ {
			compatible = "mediatek,md1_sim1_hot_plug_eint-eint";
			debounce = <0x0 0x186a0>;
			dedicated = <0x0 0x0>;
			interrupts = <0x0 0x8>;
			sockettype = <0x0 0x0>;
			src_pin = <0x0 0x1>;
			status = "okay";
		};
	};

	fragment@7 {
		target = <0xffffffff>;

		__overlay__ {
			#address-cells = <0x1>;
			#size-cells = <0x0>;

			tfa98xx@35 {
				compatible = "nxp,tfa98xx";
				pinctrl-0 = <0x1b>;
				pinctrl-1 = <0x1c>;
				pinctrl-2 = <0x1d>;
				pinctrl-names = "tfa98xx_reset_default", "tfa98xx_reset_high", "tfa98xx_reset_low";
				reg = <0x35>;
				status = "okay";
			};
		};
	};

	fragment@70 {
		target = <0xffffffff>;

		__overlay__ {
			compatible = "mediatek,md1_sim2_hot_plug_eint-eint";
			debounce = <0x1 0x186a0>;
			dedicated = <0x1 0x0>;
			interrupts = <0x1 0x8>;
			sockettype = <0x1 0x0>;
			src_pin = <0x1 0x2>;
			status = "okay";
		};
	};

	fragment@71 {
		target = <0xffffffff>;

		__overlay__ {
			regulator-default-on = <0x1>;
			regulator-name = "vcama1";
			status = "okay";
		};
	};

	fragment@72 {
		target = <0xffffffff>;

		__overlay__ {
			regulator-default-on = <0x1>;
			regulator-name = "vcama2";
			status = "okay";
		};
	};

	fragment@73 {
		target = <0xffffffff>;

		__overlay__ {
			regulator-default-on = <0x1>;
			regulator-name = "vsim1";
			status = "okay";
		};
	};

	fragment@74 {
		target = <0xffffffff>;

		__overlay__ {
			regulator-default-on = <0x1>;
			regulator-name = "vsim2";
			status = "okay";
		};
	};

	fragment@75 {
		target = <0xffffffff>;

		__overlay__ {
			regulator-default-on = <0x1>;
			regulator-name = "vcamd";
			status = "okay";
		};
	};

	fragment@76 {
		target = <0xffffffff>;

		__overlay__ {
			regulator-default-on = <0x1>;
			regulator-name = "vcamio";
			status = "okay";
		};
	};

	fragment@77 {
		target = <0xffffffff>;

		__overlay__ {
			regulator-default-on = <0x1>;
			regulator-name = "vldo28";
			status = "okay";
		};
	};

	fragment@78 {
		target = <0xffffffff>;

		__overlay__ {
			status = "okay";
			vcama-supply = <0xffffffff>;
			vcama_sub-supply = <0xffffffff>;
			vcamaf-supply = <0xffffffff>;
			vcamd-supply = <0xffffffff>;
			vcamd_sub-supply = <0xffffffff>;
			vcamio-supply = <0xffffffff>;
			vcamio_sub-supply = <0xffffffff>;
		};
	};

	fragment@79 {
		target = <0xffffffff>;

		__overlay__ {
			status = "okay";
			vtouch-supply = <0xffffffff>;
		};
	};

	fragment@8 {
		target = <0xffffffff>;

		__overlay__ {

			tfa98xxrstdefault {
				phandle = <0x1b>;
			};

			tfa98xxrsthigh {
				phandle = <0x1c>;

				pins_cmd_dat {
					output-high;
					pinmux = <0x9900>;
					slew-rate = <0x1>;
				};
			};

			tfa98xxrstlow {
				phandle = <0x1d>;

				pins_cmd_dat {
					output-low;
					pinmux = <0x9900>;
					slew-rate = <0x1>;
				};
			};
		};
	};

	fragment@80 {
		target = <0xffffffff>;

		__overlay__ {
			mediatek,kpd-hw-dl-key2 = <0x8>;
			mediatek,kpd-hw-factory-key = <0x0>;
			mediatek,kpd-hw-init-map = <0x72 0x0 0x0 0x0 0x0 0x0 0x0 0x0 0x0 0x0 0x0 0x0 0x0 0x0 0x0 0x0 0x0 0x0 0x0 0x0 0x0 0x0 0x0 0x0 0x0 0x0 0x0 0x0 0x0 0x0 0x0 0x0 0x0 0x0 0x0 0x0 0x0 0x0 0x0 0x0 0x0 0x0 0x0 0x0 0x0 0x0 0x0 0x0 0x0 0x0 0x0 0x0 0x0 0x0 0x0 0x0 0x0 0x0 0x0 0x0 0x0 0x0 0x0 0x0 0x0 0x0 0x0 0x0 0x0 0x0 0x0 0x0>;
			mediatek,kpd-hw-map-num = <0x48>;
			mediatek,kpd-hw-pwrkey = <0x8>;
			mediatek,kpd-key-debounce = <0x400>;
			mediatek,kpd-pwkey-gpio-din = <0x0>;
			mediatek,kpd-pwrkey-eint-gpio = <0x0>;
			mediatek,kpd-sw-pwrkey = <0x74>;
			mediatek,kpd-use-extend-type = <0x0>;
			status = "okay";
		};
	};

	fragment@9 {
		target = <0xffffffff>;

		__overlay__ {
			pinctrl-0 = <0x1e>;
			pinctrl-1 = <0x1f>;
			pinctrl-2 = <0x20>;
			pinctrl-3 = <0x21>;
			pinctrl-4 = <0x22>;
			pinctrl-5 = <0x23>;
			pinctrl-names = "default", "state_eint_as_int", "state_eint_output0", "state_eint_output1", "state_rst_output0", "state_rst_output1";
			status = "okay";
			tpd-filter-custom-prameters = <0x0 0x0 0x0 0x0 0x0 0x0 0x0 0x0 0x0 0x0 0x0 0x0>;
			tpd-filter-custom-speed = <0x0 0x0 0x0>;
			tpd-filter-enable = <0x1>;
			tpd-filter-pixel-density = <0x92>;
			tpd-key-dim-local = <0x5a 0x373 0x64 0x28 0xe6 0x373 0x64 0x28 0x172 0x373 0x64 0x28 0x0 0x0 0x0 0x0>;
			tpd-key-local = <0x8b 0xac 0x9e 0x0>;
			tpd-key-num = <0x3>;
			tpd-max-touch-num = <0x5>;
			tpd-resolution = <0x438 0x780>;
			use-tpd-button = <0x0>;
		};
	};
};
